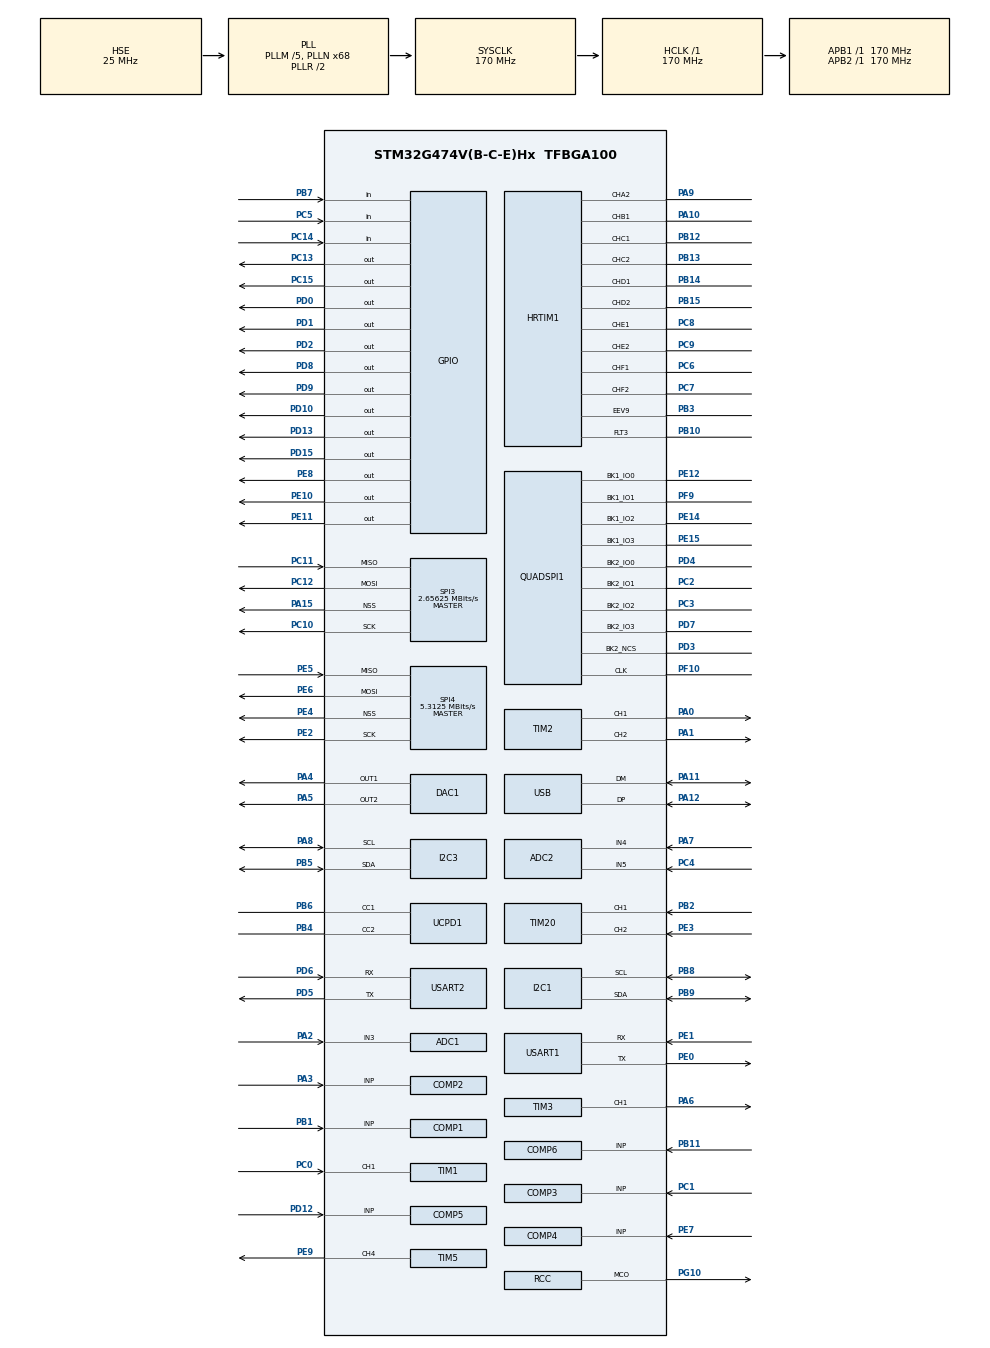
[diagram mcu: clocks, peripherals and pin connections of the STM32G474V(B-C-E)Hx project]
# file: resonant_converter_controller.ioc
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ADC1.Channel-1\#ChannelRegularConversion=ADC_CHANNEL_3
ADC1.EnableInjectedConversion=ENABLE
ADC1.ExternalTrigInjecConv=ADC_EXTERNALTRIGINJEC_T8_TRGO
ADC1.InjNumberOfConversion=1
ADC1.InjectedChannel-2\#ChannelInjectedConversion=ADC_CHANNEL_3
ADC1.InjectedOffsetNumber-2\#ChannelInjectedConversion=ADC_OFFSET_NONE
ADC1.InjectedRank-2\#ChannelInjectedConversion=1
ADC1.InjectedSamplingTime-2\#ChannelInjectedConversion=ADC_SAMPLETIME_2CYCLES_5
ADC1.NbrOfConversion=1
ADC1.NbrOfConversionFlag=1
ADC1.OffsetNumber-1\#ChannelRegularConversion=ADC_OFFSET_NONE
ADC1.Rank-1\#ChannelRegularConversion=1
ADC1.Rank1_Channel=ADC_CHANNEL_3
ADC1.Rank2_Channel=ADC_CHANNEL_3
ADC1.Rank3_Channel=ADC_CHANNEL_3
ADC1.SamplingTime-1\#ChannelRegularConversion=ADC_SAMPLETIME_2CYCLES_5
ADC1.master=1
ADC2.Channel-0\#ChannelRegularConversion=ADC_CHANNEL_4
ADC2.EnableInjectedConversion=ENABLE
ADC2.ExternalTrigInjecConv=ADC_EXTERNALTRIGINJEC_T8_TRGO
ADC2.InjNumberOfConversion=1
ADC2.InjectedChannel-1\#ChannelInjectedConversion=ADC_CHANNEL_4
ADC2.InjectedOffsetNumber-1\#ChannelInjectedConversion=ADC_OFFSET_NONE
ADC2.InjectedRank-1\#ChannelInjectedConversion=1
ADC2.InjectedSamplingTime-1\#ChannelInjectedConversion=ADC_SAMPLETIME_2CYCLES_5
ADC2.NbrOfConversion=1
ADC2.NbrOfConversionFlag=1
ADC2.OffsetNumber-0\#ChannelRegularConversion=ADC_OFFSET_NONE
ADC2.Rank-0\#ChannelRegularConversion=1
ADC2.Rank1_Channel=ADC_CHANNEL_4
ADC2.SamplingTime-0\#ChannelRegularConversion=ADC_SAMPLETIME_2CYCLES_5
ADC3.Channel-0\#ChannelRegularConversion=ADC_CHANNEL_9
ADC3.EnableInjectedConversion=ENABLE
ADC3.ExternalTrigInjecConv=ADC_EXTERNALTRIGINJEC_T8_TRGO
ADC3.InjNumberOfConversion=1
ADC3.InjectedChannel-1\#ChannelInjectedConversion=ADC_CHANNEL_9
ADC3.InjectedOffsetNumber-1\#ChannelInjectedConversion=ADC_OFFSET_NONE
ADC3.InjectedRank-1\#ChannelInjectedConversion=1
ADC3.InjectedSamplingTime-1\#ChannelInjectedConversion=ADC_SAMPLETIME_2CYCLES_5
ADC3.NbrOfConversionFlag=1
ADC3.OffsetNumber-0\#ChannelRegularConversion=ADC_OFFSET_NONE
ADC3.Rank-0\#ChannelRegularConversion=1
ADC3.Rank1_Channel=ADC_CHANNEL_9
ADC3.SamplingTime-0\#ChannelRegularConversion=ADC_SAMPLETIME_2CYCLES_5
ADC3.master=1
DAC1.DAC_Channel-DAC_OUT2=DAC_CHANNEL_2
DAC3.DAC_Channel-DAC_OUT2_Int=DAC_CHANNEL_2
DAC4.DAC_Channel-DAC_OUT2_Int=DAC_CHANNEL_2
Dma.ADC1.6.Direction=DMA_PERIPH_TO_MEMORY
Dma.ADC1.6.EventEnable=DISABLE
Dma.ADC1.6.Instance=DMA1_Channel7
Dma.ADC1.6.MemDataAlignment=DMA_MDATAALIGN_HALFWORD
Dma.ADC1.6.MemInc=DMA_MINC_ENABLE
Dma.ADC1.6.Mode=DMA_NORMAL
Dma.ADC1.6.PeriphDataAlignment=DMA_PDATAALIGN_HALFWORD
Dma.ADC1.6.PeriphInc=DMA_PINC_DISABLE
Dma.ADC1.6.Polarity=HAL_DMAMUX_REQ_GEN_RISING
Dma.ADC1.6.Priority=DMA_PRIORITY_HIGH
Dma.ADC1.6.RequestNumber=1
Dma.ADC1.6.SignalID=NONE
Dma.ADC1.6.SyncEnable=DISABLE
Dma.ADC1.6.SyncPolarity=HAL_DMAMUX_SYNC_NO_EVENT
Dma.ADC1.6.SyncRequestNumber=1
Dma.ADC1.6.SyncSignalID=NONE
Dma.ADC2.5.Direction=DMA_PERIPH_TO_MEMORY
Dma.ADC2.5.EventEnable=DISABLE
Dma.ADC2.5.Instance=DMA1_Channel6
Dma.ADC2.5.MemDataAlignment=DMA_MDATAALIGN_HALFWORD
Dma.ADC2.5.MemInc=DMA_MINC_ENABLE
Dma.ADC2.5.Mode=DMA_NORMAL
Dma.ADC2.5.PeriphDataAlignment=DMA_PDATAALIGN_HALFWORD
Dma.ADC2.5.PeriphInc=DMA_PINC_DISABLE
Dma.ADC2.5.Polarity=HAL_DMAMUX_REQ_GEN_RISING
Dma.ADC2.5.Priority=DMA_PRIORITY_HIGH
Dma.ADC2.5.RequestNumber=1
Dma.ADC2.5.SignalID=NONE
Dma.ADC2.5.SyncEnable=DISABLE
Dma.ADC2.5.SyncPolarity=HAL_DMAMUX_SYNC_NO_EVENT
Dma.ADC2.5.SyncRequestNumber=1
Dma.ADC2.5.SyncSignalID=NONE
Dma.ADC3.4.Direction=DMA_PERIPH_TO_MEMORY
Dma.ADC3.4.EventEnable=DISABLE
Dma.ADC3.4.Instance=DMA1_Channel5
Dma.ADC3.4.MemDataAlignment=DMA_MDATAALIGN_HALFWORD
Dma.ADC3.4.MemInc=DMA_MINC_ENABLE
Dma.ADC3.4.Mode=DMA_NORMAL
Dma.ADC3.4.PeriphDataAlignment=DMA_PDATAALIGN_HALFWORD
Dma.ADC3.4.PeriphInc=DMA_PINC_DISABLE
Dma.ADC3.4.Polarity=HAL_DMAMUX_REQ_GEN_RISING
Dma.ADC3.4.Priority=DMA_PRIORITY_HIGH
Dma.ADC3.4.RequestNumber=1
Dma.ADC3.4.SignalID=NONE
Dma.ADC3.4.SyncEnable=DISABLE
Dma.ADC3.4.SyncPolarity=HAL_DMAMUX_SYNC_NO_EVENT
Dma.ADC3.4.SyncRequestNumber=1
Dma.ADC3.4.SyncSignalID=NONE
Dma.DAC1_CH1.2.Direction=DMA_MEMORY_TO_PERIPH
Dma.DAC1_CH1.2.EventEnable=DISABLE
Dma.DAC1_CH1.2.Instance=DMA1_Channel3
Dma.DAC1_CH1.2.MemDataAlignment=DMA_MDATAALIGN_HALFWORD
Dma.DAC1_CH1.2.MemInc=DMA_MINC_ENABLE
Dma.DAC1_CH1.2.Mode=DMA_NORMAL
Dma.DAC1_CH1.2.PeriphDataAlignment=DMA_PDATAALIGN_WORD
Dma.DAC1_CH1.2.PeriphInc=DMA_PINC_DISABLE
Dma.DAC1_CH1.2.Polarity=HAL_DMAMUX_REQ_GEN_RISING
Dma.DAC1_CH1.2.Priority=DMA_PRIORITY_LOW
Dma.DAC1_CH1.2.RequestNumber=1
Dma.DAC1_CH1.2.SignalID=NONE
Dma.DAC1_CH1.2.SyncEnable=DISABLE
Dma.DAC1_CH1.2.SyncPolarity=HAL_DMAMUX_SYNC_NO_EVENT
Dma.DAC1_CH1.2.SyncRequestNumber=1
Dma.DAC1_CH1.2.SyncSignalID=NONE
Dma.DAC1_CH2.3.Direction=DMA_MEMORY_TO_PERIPH
Dma.DAC1_CH2.3.EventEnable=DISABLE
Dma.DAC1_CH2.3.Instance=DMA1_Channel4
Dma.DAC1_CH2.3.MemDataAlignment=DMA_MDATAALIGN_HALFWORD
Dma.DAC1_CH2.3.MemInc=DMA_MINC_ENABLE
Dma.DAC1_CH2.3.Mode=DMA_NORMAL
Dma.DAC1_CH2.3.PeriphDataAlignment=DMA_PDATAALIGN_WORD
Dma.DAC1_CH2.3.PeriphInc=DMA_PINC_DISABLE
Dma.DAC1_CH2.3.Polarity=HAL_DMAMUX_REQ_GEN_RISING
Dma.DAC1_CH2.3.Priority=DMA_PRIORITY_LOW
Dma.DAC1_CH2.3.RequestNumber=1
Dma.DAC1_CH2.3.SignalID=NONE
Dma.DAC1_CH2.3.SyncEnable=DISABLE
Dma.DAC1_CH2.3.SyncPolarity=HAL_DMAMUX_SYNC_NO_EVENT
Dma.DAC1_CH2.3.SyncRequestNumber=1
Dma.DAC1_CH2.3.SyncSignalID=NONE
Dma.QUADSPI.7.Direction=DMA_MEMORY_TO_PERIPH
Dma.QUADSPI.7.EventEnable=DISABLE
Dma.QUADSPI.7.Instance=DMA1_Channel8
Dma.QUADSPI.7.MemDataAlignment=DMA_MDATAALIGN_BYTE
Dma.QUADSPI.7.MemInc=DMA_MINC_ENABLE
Dma.QUADSPI.7.Mode=DMA_NORMAL
Dma.QUADSPI.7.PeriphDataAlignment=DMA_PDATAALIGN_HALFWORD
Dma.QUADSPI.7.PeriphInc=DMA_PINC_DISABLE
Dma.QUADSPI.7.Polarity=HAL_DMAMUX_REQ_GEN_RISING
Dma.QUADSPI.7.Priority=DMA_PRIORITY_VERY_HIGH
Dma.QUADSPI.7.RequestNumber=1
Dma.QUADSPI.7.SignalID=NONE
Dma.QUADSPI.7.SyncEnable=DISABLE
Dma.QUADSPI.7.SyncPolarity=HAL_DMAMUX_SYNC_NO_EVENT
Dma.QUADSPI.7.SyncRequestNumber=1
Dma.QUADSPI.7.SyncSignalID=NONE
Dma.Request0=UCPD1_RX
Dma.Request1=UCPD1_TX
Dma.Request2=DAC1_CH1
Dma.Request3=DAC1_CH2
Dma.Request4=ADC3
Dma.Request5=ADC2
Dma.Request6=ADC1
Dma.Request7=QUADSPI
Dma.UCPD1_RX.0.Direction=DMA_PERIPH_TO_MEMORY
Dma.UCPD1_RX.0.EventEnable=DISABLE
Dma.UCPD1_RX.0.Instance=DMA1_Channel1
Dma.UCPD1_RX.0.MemDataAlignment=DMA_MDATAALIGN_BYTE
Dma.UCPD1_RX.0.MemInc=DMA_MINC_ENABLE
Dma.UCPD1_RX.0.Mode=DMA_NORMAL
Dma.UCPD1_RX.0.PeriphDataAlignment=DMA_PDATAALIGN_BYTE
Dma.UCPD1_RX.0.PeriphInc=DMA_PINC_DISABLE
Dma.UCPD1_RX.0.Polarity=HAL_DMAMUX_REQ_GEN_RISING
Dma.UCPD1_RX.0.Priority=DMA_PRIORITY_LOW
Dma.UCPD1_RX.0.RequestNumber=1
Dma.UCPD1_RX.0.SignalID=NONE
Dma.UCPD1_RX.0.SyncEnable=DISABLE
Dma.UCPD1_RX.0.SyncPolarity=HAL_DMAMUX_SYNC_NO_EVENT
Dma.UCPD1_RX.0.SyncRequestNumber=1
Dma.UCPD1_RX.0.SyncSignalID=NONE
Dma.UCPD1_TX.1.Direction=DMA_MEMORY_TO_PERIPH
Dma.UCPD1_TX.1.EventEnable=DISABLE
Dma.UCPD1_TX.1.Instance=DMA1_Channel2
Dma.UCPD1_TX.1.MemDataAlignment=DMA_MDATAALIGN_BYTE
Dma.UCPD1_TX.1.MemInc=DMA_MINC_ENABLE
Dma.UCPD1_TX.1.Mode=DMA_NORMAL
Dma.UCPD1_TX.1.PeriphDataAlignment=DMA_PDATAALIGN_BYTE
Dma.UCPD1_TX.1.PeriphInc=DMA_PINC_DISABLE
Dma.UCPD1_TX.1.Polarity=HAL_DMAMUX_REQ_GEN_RISING
Dma.UCPD1_TX.1.Priority=DMA_PRIORITY_LOW
Dma.UCPD1_TX.1.RequestNumber=1
Dma.UCPD1_TX.1.SignalID=NONE
Dma.UCPD1_TX.1.SyncEnable=DISABLE
Dma.UCPD1_TX.1.SyncPolarity=HAL_DMAMUX_SYNC_NO_EVENT
Dma.UCPD1_TX.1.SyncRequestNumber=1
Dma.UCPD1_TX.1.SyncSignalID=NONE
FREERTOS.Tasks01=defaultTask,24,128,StartDefaultTask,Default,NULL,Dynamic,NULL,NULL
HRTIM1.Event_EEV1=HRTIM_EVENT_1
HRTIM1.Event_EEV2=HRTIM_EVENT_2
HRTIM1.Event_EEV3=__NULL
HRTIM1.Event_EEV4=HRTIM_EVENT_4
HRTIM1.Event_EEV5=HRTIM_EVENT_5
HRTIM1.Event_EEV8=HRTIM_EVENT_8
I2C1.Timing=0x40B285C2
I2C3.Timing=0x40B285C2
Mcu.Family=STM32G4
Mcu.Name=STM32G474V(B-C-E)Hx
Mcu.Package=TFBGA100
NVIC.DMA1_Channel1_IRQn=true\:5\:0\:false\:false\:true\:true\:false\:true\:true
NVIC.DMA1_Channel2_IRQn=true\:5\:0\:false\:false\:true\:true\:false\:true\:true
NVIC.DMA1_Channel3_IRQn=true\:5\:0\:false\:false\:true\:true\:false\:true\:true
NVIC.DMA1_Channel4_IRQn=true\:5\:0\:false\:false\:true\:true\:false\:true\:true
NVIC.DMA1_Channel5_IRQn=true\:5\:0\:false\:false\:true\:true\:false\:true\:true
NVIC.DMA1_Channel6_IRQn=true\:5\:0\:false\:false\:true\:true\:false\:true\:true
NVIC.DMA1_Channel7_IRQn=true\:5\:0\:false\:false\:true\:true\:false\:true\:true
NVIC.DMA1_Channel8_IRQn=true\:5\:0\:false\:false\:true\:true\:false\:true\:true
NVIC.PriorityGroup=NVIC_PRIORITYGROUP_4
NVIC.TIM7_DAC_IRQn=true\:15\:0\:false\:false\:true\:false\:false\:true\:true
NVIC.TimeBase=TIM7_DAC_IRQn
NVIC.TimeBaseIP=TIM7
NVIC.UCPD1_IRQn=true\:5\:0\:false\:false\:true\:true\:true\:false\:true
NVIC.USB_LP_IRQn=true\:5\:0\:false\:false\:true\:true\:false\:true\:true
PA0.Signal=S_TIM2_CH1
PA1.Signal=S_TIM2_CH2
PA10.Mode=Output_TB1
PA10.Signal=HRTIM1_CHB1
PA11.Mode=Device
PA11.Signal=USB_DM
PA12.Mode=Device
PA12.Signal=USB_DP
PA13.Mode=Serial_Wire
PA13.Signal=SYS_JTMS-SWDIO
PA14.Mode=Serial_Wire
PA14.Signal=SYS_JTCK-SWCLK
PA15.Mode=NSS_Signal_Hard_Output
PA15.Signal=SPI3_NSS
PA2.Mode=IN3-Single-Ended
PA2.Signal=ADC1_IN3
PA3.Signal=SharedAnalog_PA3
PA4.Signal=COMP_DAC11_group
PA5.Signal=COMP_DAC12_group
PA6.Signal=S_TIM3_CH1
PA7.Mode=IN4-Single-Ended
PA7.Signal=ADC2_IN4
PA8.Mode=I2C
PA8.Signal=I2C3_SCL
PA9.Mode=Output_TA2
PA9.Signal=HRTIM1_CHA2
PB1.Signal=SharedAnalog_PB1
PB10.Mode=Fault_Enable3
PB10.Signal=HRTIM1_FLT3
PB11.Signal=SharedAnalog_PB11
PB12.Mode=Output_TC1TC2
PB12.Signal=HRTIM1_CHC1
PB13.Mode=Output_TC1TC2
PB13.Signal=HRTIM1_CHC2
PB14.Mode=Output_TD1TD2
PB14.Signal=HRTIM1_CHD1
PB15.Mode=Output_TD1TD2
PB15.Signal=HRTIM1_CHD2
PB2.Signal=S_TIM20_CH1
PB3.Mode=External_Evt_enable9
PB3.Signal=HRTIM1_EEV9
PB4.Mode=Dual_Role_AllSignals
PB4.Signal=UCPD1_CC2
PB5.Mode=I2C
PB5.Signal=I2C3_SDA
PB6.Mode=Dual_Role_AllSignals
PB6.Signal=UCPD1_CC1
PB7.Signal=GPIO_Input
PB8-BOOT0.Mode=I2C
PB8-BOOT0.Signal=I2C1_SCL
PB9.Mode=I2C
PB9.Signal=I2C1_SDA
PC0.Signal=S_TIM1_CH1
PC1.Signal=SharedAnalog_PC1
PC10.Mode=Full_Duplex_Master
PC10.Signal=SPI3_SCK
PC11.Mode=Full_Duplex_Master
PC11.Signal=SPI3_MISO
PC12.Mode=Full_Duplex_Master
PC12.Signal=SPI3_MOSI
PC13.Signal=GPIO_Output
PC14-OSC32_IN.Signal=GPIO_Input
PC15-OSC32_OUT.Signal=GPIO_Output
PC2.Mode=Dual Bank
PC2.Signal=QUADSPI1_BK2_IO1
PC3.Mode=Dual Bank
PC3.Signal=QUADSPI1_BK2_IO2
PC4.Mode=IN5-Single-Ended
PC4.Signal=ADC2_IN5
PC5.Signal=GPIO_Input
PC6.Mode=Output_TF1TF2
PC6.Signal=HRTIM1_CHF1
PC7.Mode=Output_TF1TF2
PC7.Signal=HRTIM1_CHF2
PC8.Mode=Output_TE1TE2
PC8.Signal=HRTIM1_CHE1
PC9.Mode=Output_TE1TE2
PC9.Signal=HRTIM1_CHE2
PD0.Signal=GPIO_Output
PD1.Signal=GPIO_Output
PD10.Signal=GPIO_Output
PD12.Signal=SharedAnalog_PD12
PD13.Signal=GPIO_Output
PD15.Signal=GPIO_Output
PD2.Signal=GPIO_Output
PD3.Mode=Enable Chip Select 2 for both banks
PD3.Signal=QUADSPI1_BK2_NCS
PD4.Mode=Dual Bank
PD4.Signal=QUADSPI1_BK2_IO0
PD5.Mode=Asynchronous
PD5.Signal=USART2_TX
PD6.Mode=Asynchronous
PD6.Signal=USART2_RX
PD7.Mode=Dual Bank
PD7.Signal=QUADSPI1_BK2_IO3
PD8.Signal=GPIO_Output
PD9.Signal=GPIO_Output
PE0.Mode=Asynchronous
PE0.Signal=USART1_TX
PE1.Mode=Asynchronous
PE1.Signal=USART1_RX
PE10.Signal=GPIO_Output
PE11.Signal=GPIO_Output
PE12.Mode=Dual Bank
PE12.Signal=QUADSPI1_BK1_IO0
PE14.Mode=Dual Bank
PE14.Signal=QUADSPI1_BK1_IO2
PE15.Mode=Dual Bank
PE15.Signal=QUADSPI1_BK1_IO3
PE2.Mode=Full_Duplex_Master
PE2.Signal=SPI4_SCK
PE3.Signal=S_TIM20_CH2
PE4.Mode=NSS_Signal_Hard_Output
PE4.Signal=SPI4_NSS
PE5.Mode=Full_Duplex_Master
PE5.Signal=SPI4_MISO
PE6.Mode=Full_Duplex_Master
PE6.Signal=SPI4_MOSI
PE7.Signal=SharedAnalog_PE7
PE8.Signal=GPIO_Output
PE9.Signal=S_TIM5_CH4
PF0-OSC_IN.Mode=HSE-External-Oscillator
PF0-OSC_IN.Signal=RCC_OSC_IN
PF1-OSC_OUT.Mode=HSE-External-Oscillator
PF1-OSC_OUT.Signal=RCC_OSC_OUT
PF10.Mode=Dual Bank
PF10.Signal=QUADSPI1_CLK
PF9.Mode=Dual Bank
PF9.Signal=QUADSPI1_BK1_IO1
PG10-NRST.Mode=Clock-out
PG10-NRST.Signal=RCC_MCO
ProjectManager.HeapSize=0x200
ProjectManager.StackSize=0x400
ProjectManager.TargetToolchain=CMake
RCC.ADC12Freq_Value=170000000
RCC.ADC345Freq_Value=170000000
RCC.AHBFreq_Value=170000000
RCC.APB1Freq_Value=170000000
RCC.APB1TimFreq_Value=170000000
RCC.APB2Freq_Value=170000000
RCC.APB2TimFreq_Value=170000000
RCC.CK48CLockSelection=RCC_USBCLKSOURCE_HSI48
RCC.CortexFreq_Value=170000000
RCC.EXTERNAL_CLOCK_VALUE=12288000
RCC.HCLKFreq_Value=170000000
RCC.HSE_VALUE=25000000
RCC.HSI48_VALUE=48000000
RCC.HSI_VALUE=16000000
RCC.LSE_VALUE=32768
RCC.PLLM=RCC_PLLM_DIV5
RCC.PLLN=68
RCC.PLLQ=RCC_PLLQ_DIV8
RCC.PLLSourceVirtual=RCC_PLLSOURCE_HSE
RCC.PREFETCH_ENABLE=1
RCC.RCC_MCO1Source=RCC_MCO1SOURCE_HSE
RCC.SYSCLKFreq_VALUE=170000000
RCC.SYSCLKSource=RCC_SYSCLKSOURCE_PLLCLK
RCC.USBFreq_Value=48000000
RCC.VCOOutputFreq_Value=340000000
SH.COMP_DAC11_group.0=DAC1_OUT1,DAC_OUT1
SH.COMP_DAC12_group.0=DAC1_OUT2,DAC_OUT2
SH.S_TIM1_CH1.0=TIM1_CH1,TriggerSource_TI1ED
SH.S_TIM20_CH1.0=TIM20_CH1,Encoder_Interface
SH.S_TIM20_CH2.0=TIM20_CH2,Encoder_Interface
SH.S_TIM2_CH1.0=TIM2_CH1,PWM Generation1 CH1
SH.S_TIM2_CH2.0=TIM2_CH2,PWM Generation2 CH2
SH.S_TIM3_CH1.0=TIM3_CH1,PWM Generation1 CH1
SH.S_TIM5_CH4.0=TIM5_CH4,PWM Generation4 CH4
SH.SharedAnalog_PA3.0=ADC1_IN4
SH.SharedAnalog_PA3.1=COMP2_INP,INP
SH.SharedAnalog_PB1.0=ADC3_IN1
SH.SharedAnalog_PB1.1=COMP1_INP,INP
SH.SharedAnalog_PB11.0=COMP6_INP,INP
SH.SharedAnalog_PB11.1=ADC1_IN14,IN14-Single-Ended
SH.SharedAnalog_PC1.0=ADC1_IN7
SH.SharedAnalog_PC1.1=COMP3_INP,INP
SH.SharedAnalog_PD12.0=COMP5_INP,INP
SH.SharedAnalog_PD12.1=ADC3_IN9,IN9-Single-Ended
SH.SharedAnalog_PE7.0=ADC3_IN4
SH.SharedAnalog_PE7.1=COMP4_INP,INP
SPI3.BaudRatePrescaler=SPI_BAUDRATEPRESCALER_64
SPI3.CalculateBaudRate=2.65625 MBits/s
SPI3.Direction=SPI_DIRECTION_2LINES
SPI3.Mode=SPI_MODE_MASTER
SPI3.VirtualNSS=VM_NSSHARD
SPI3.VirtualType=VM_MASTER
SPI4.BaudRatePrescaler=SPI_BAUDRATEPRESCALER_32
SPI4.CalculateBaudRate=5.3125 MBits/s
SPI4.Direction=SPI_DIRECTION_2LINES
SPI4.Mode=SPI_MODE_MASTER
SPI4.VirtualNSS=VM_NSSHARD
SPI4.VirtualType=VM_MASTER
SYS.TrimmingMode=__NULL
SYS.VoltageScaling=SYSCFG_VREFBUF_VOLTAGE_SCALE2
TIM1.Channel-Input_Capture1_from_TRC=TIM_CHANNEL_1
TIM2.Channel-PWM\ Generation1\ CH1=TIM_CHANNEL_1
TIM2.Channel-PWM\ Generation2\ CH2=TIM_CHANNEL_2
TIM3.Channel-PWM\ Generation1\ CH1=TIM_CHANNEL_1
TIM5.Channel-PWM\ Generation4\ CH4=TIM_CHANNEL_4
TIM8.TIM_MasterOutputTrigger=TIM_TRGO_UPDATE
USART1.VirtualMode-Asynchronous=VM_ASYNC
USART2.VirtualMode-Asynchronous=VM_ASYNC
USBPD.USBPD_PORT0_PDO_SNK_FIXED_SET_OP_CURRENT_0=2000
USB_DEVICE.CLASS_NAME_FS=CDC
USB_DEVICE.VirtualMode=Cdc
USB_DEVICE.VirtualModeFS=Cdc_FS
VP_COMP1_VS_DAC3OUT1.Mode=INM_DAC3OUT1
VP_COMP2_VS_DAC3OUT2.Mode=INM_DAC3OUT2
VP_COMP3_VS_DAC3OUT1.Mode=INM_DAC3OUT1
VP_COMP4_VS_DAC3OUT2.Mode=INM_DAC3OUT2
VP_COMP5_VS_DAC4OUT1.Mode=INM_DAC4OUT1
VP_COMP6_VS_DAC4OUT2.Mode=INM_DAC4OUT2
VP_CRC_VS_CRC.Mode=CRC_Activate
VP_DAC2_VS_DACI1.Mode=DAC_OUT1_Int
VP_DAC3_VS_DACI1.Mode=DAC_OUT1_Int
VP_DAC3_VS_DACI2.Mode=DAC_OUT2_Int
VP_DAC4_VS_DACI1.Mode=DAC_OUT1_Int
VP_DAC4_VS_DACI2.Mode=DAC_OUT2_Int
VP_FATFS_VS_Generic.Mode=User_defined
VP_FREERTOS_VS_CMSIS_V2.Mode=CMSIS_V2
VP_HRTIM1_VS_hrtimMasterTimerNoOutput.Mode=MasterTimer
VP_HRTIM1_VirtualSync.Mode=SCOUT_SCINmodeVirtual
VP_SYS_VS_DBSignals.Mode=DisableDeadBatterySignals
VP_SYS_VS_tim7.Mode=TIM7
VP_TIM1_VS_CH1.Mode=Input_Capture1_from_TRC
VP_TIM1_VS_ClockSourceINT.Mode=Internal
VP_TIM1_VS_ControllerModeTrigger.Mode=Trigger Mode
VP_TIM2_VS_ClockSourceINT.Mode=Internal
VP_TIM3_VS_ClockSourceINT.Mode=Internal
VP_TIM5_VS_ClockSourceINT.Mode=Internal
VP_TIM8_VS_ClockSourceINT.Mode=Internal
VP_USBPD_VS_PD3FULL.Mode=PD3_Full_Stack
VP_USBPD_VS_USBPD1.Mode=USBPD_P0
VP_USBPD_VS_usbpd_tim4.Mode=TIM4
VP_USB_DEVICE_VS_USB_DEVICE_CDC_FS.Mode=CDC_FS
VREF+.Mode=InternalMode
VREF+.Signal=VREFBUF_OUT
board=custom

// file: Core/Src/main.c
/* USER CODE BEGIN Header */
/**
  ******************************************************************************
  * @file           : main.c
  * @brief          : Main program body
  ******************************************************************************
  * @attention
  *
  * Copyright (c) 2025 STMicroelectronics.
  * All rights reserved.
  *
  * This software is licensed under terms that can be found in the LICENSE file
  * in the root directory of this software component.
  * If no LICENSE file comes with this software, it is provided AS-IS.
  *
  ******************************************************************************
  */
/* USER CODE END Header */
#include "main.h"
#include "cmsis_os.h"
#include "app_fatfs.h"
#include "usbpd.h"
#include "usb_device.h"

/* USER CODE BEGIN Includes */

#include "board.h"
#include "usbpd_app.h"
#include "usbpd_dpm_core.h"

/* USER CODE END Includes */

ADC_HandleTypeDef hadc1;
ADC_HandleTypeDef hadc2;
ADC_HandleTypeDef hadc3;
DMA_HandleTypeDef hdma_adc1;
DMA_HandleTypeDef hdma_adc2;
DMA_HandleTypeDef hdma_adc3;

COMP_HandleTypeDef hcomp1;
COMP_HandleTypeDef hcomp2;
COMP_HandleTypeDef hcomp3;
COMP_HandleTypeDef hcomp4;
COMP_HandleTypeDef hcomp5;
COMP_HandleTypeDef hcomp6;

CRC_HandleTypeDef hcrc;

DAC_HandleTypeDef hdac1;
DAC_HandleTypeDef hdac2;
DAC_HandleTypeDef hdac3;
DAC_HandleTypeDef hdac4;
DMA_HandleTypeDef hdma_dac1_ch1;
DMA_HandleTypeDef hdma_dac1_ch2;

HRTIM_HandleTypeDef hhrtim1;

I2C_HandleTypeDef hi2c1;
I2C_HandleTypeDef hi2c3;

QSPI_HandleTypeDef hqspi1;
DMA_HandleTypeDef hdma_quadspi;

SPI_HandleTypeDef hspi3;
SPI_HandleTypeDef hspi4;

TIM_HandleTypeDef htim1;
TIM_HandleTypeDef htim2;
TIM_HandleTypeDef htim3;
TIM_HandleTypeDef htim5;
TIM_HandleTypeDef htim8;
TIM_HandleTypeDef htim20;

UART_HandleTypeDef huart1;
UART_HandleTypeDef huart2;

/* Definitions for defaultTask */
osThreadId_t defaultTaskHandle;
const osThreadAttr_t defaultTask_attributes = {
  .name = "defaultTask",
  .priority = (osPriority_t) osPriorityNormal,
  .stack_size = 128 * 4
};
/* USER CODE BEGIN PV */
// Board definition macro (selected by CMake -DBOARD=...)
#define resonance_converter_controller

/* Board config - pointers for board.h extern declarations */
HRTIM_HandleTypeDef *g_board_hrtim = &hhrtim1;
const uint32_t g_board_hrtim_out1 = HRTIM_OUTPUT_TA2;
const uint32_t g_board_hrtim_out2 = HRTIM_OUTPUT_TB1;
const uint32_t g_board_hrtim_out3 = HRTIM_OUTPUT_TC1;
const uint32_t g_board_hrtim_out4 = HRTIM_OUTPUT_TC2;
const uint32_t g_board_hrtim_sync_out1_p = HRTIM_OUTPUT_TD1;
const uint32_t g_board_hrtim_sync_out1_n = HRTIM_OUTPUT_TD2;
const uint32_t g_board_hrtim_sync_out2_p = HRTIM_OUTPUT_TE1;
const uint32_t g_board_hrtim_sync_out2_n = HRTIM_OUTPUT_TE2;
const uint32_t g_board_hrtim_sync_out3_p = HRTIM_OUTPUT_TF1;
const uint32_t g_board_hrtim_sync_out3_n = HRTIM_OUTPUT_TF2;
const uint32_t g_board_hrtim_delayd_eev1 = HRTIM_EVENT_9;
const uint32_t g_board_hrtim_flt = HRTIM_FAULT_3;

TIM_HandleTypeDef *g_board_tim_feedback = &htim1;
const uint32_t g_board_tim_feedback_channel = TIM_CHANNEL_1;

TIM_HandleTypeDef *g_board_aux_pwm = &htim2;
const uint32_t g_board_aux_pwm_cha = TIM_CHANNEL_1;
const uint32_t g_board_aux_pwm_chb = TIM_CHANNEL_2;

TIM_HandleTypeDef *g_board_tim_fan_pwm = &htim3;
const uint32_t g_board_tim_fan_pwm_channel = TIM_CHANNEL_1;

TIM_HandleTypeDef *g_board_tim_ws2812b = &htim5;
const uint32_t g_board_tim_ws2812b_channel = TIM_CHANNEL_4;

TIM_HandleTypeDef *g_board_tim_encoder = &htim20;

TIM_HandleTypeDef *g_board_tim_adc_trgo = &htim8;

I2C_HandleTypeDef *g_board_i2c_internal = &hi2c1;
I2C_HandleTypeDef *g_board_i2c_external = &hi2c3;
SPI_HandleTypeDef *g_board_lcd_spi = &hspi3;
SPI_HandleTypeDef *g_board_sdcard_spi = &hspi4;
QSPI_HandleTypeDef *g_board_psram_qspi = &hqspi1;
UART_HandleTypeDef *g_board_ctl_uart = &huart1;
UART_HandleTypeDef *g_board_aux_uart = &huart2;

CRC_HandleTypeDef *g_board_crc32 = &hcrc;

DAC_HandleTypeDef *g_board_dac_ch1 = &hdac1;
DAC_HandleTypeDef *g_board_dac_ch2 = &hdac2;
DAC_HandleTypeDef *g_board_dac_ch3 = &hdac3;
DAC_HandleTypeDef *g_board_dac_ch4 = &hdac4;
DAC_HandleTypeDef *g_board_dac_channels[4] = { &hdac1, &hdac2, &hdac3, &hdac4 };

// BOARD_CONFIG instance - references to board peripherals
struct BoardConfig g_board_config = {
    .message_bus = &huart1,
    .crc32 = &hcrc
};

DAC_channel_t g_board_fb_sync_v = {
    .DACx = &hdac1, .channel = DAC_CHANNEL_2
};
DAC_channel_t g_board_dac_aux_v = {
    .DACx = &hdac1, .channel = DAC_CHANNEL_1
};
DAC_channel_t g_board_fb_ocd_comp_v = {
    .DACx = &hdac4, .channel = DAC_CHANNEL_2
};
DAC_channel_t g_board_fb_ocd2_comp_v = {
    .DACx = &hdac4, .channel = DAC_CHANNEL_1
};

ADC_channel_t g_board_aux_adc_read_v = {
    .ADCx = &hadc2, .channel = ADC_CHANNEL_4
};
ADC_channel_t g_board_dac_aux_read_back_v = {
    .ADCx = &hadc2, .channel = ADC_CHANNEL_5
};

ADC_channel_t g_board_fb_ocd_read_v = {
    .ADCx = &hadc1, .channel = ADC_CHANNEL_14
};
ADC_channel_t g_board_fb_ocd2_read_v = {
    .ADCx = &hadc3, .channel = ADC_CHANNEL_9
};

ADC_channel_t g_board_vsense_read_v = {
    .ADCx = &hadc3, .channel = ADC_CHANNEL_3
};

DAC_channel_t g_board_isense_comp_v[4] = {
    { .DACx = &hdac3, .channel = DAC_CHANNEL_2 },
    { .DACx = &hdac3, .channel = DAC_CHANNEL_2 },
    { .DACx = &hdac3, .channel = DAC_CHANNEL_1 },
    { .DACx = &hdac3, .channel = DAC_CHANNEL_1 },
};

COMP_HandleTypeDef *g_board_isense[4] = {
    &hcomp2,
    &hcomp4,
    &hcomp1,
    &hcomp3,
};
COMP_HandleTypeDef *g_board_fb_ocd2 = &hcomp5;
COMP_HandleTypeDef *g_board_fb_ocd = &hcomp6;

GPIO_pin_t g_board_gpios[8] = {
    { .GPIOx = GPIOD, .pin = GPIO_PIN_10 },
    { .GPIOx = GPIOD, .pin = GPIO_PIN_9 },
    { .GPIOx = GPIOD, .pin = GPIO_PIN_13 },
    { .GPIOx = GPIOD, .pin = GPIO_PIN_15 },
    { .GPIOx = GPIOE, .pin = GPIO_PIN_8 },
    { .GPIOx = GPIOD, .pin = GPIO_PIN_8 },
    { .GPIOx = GPIOE, .pin = GPIO_PIN_11 },
    { .GPIOx = GPIOE, .pin = GPIO_PIN_10 },
};
GPIO_pin_t g_board_power_int = {
    .GPIOx = GPIOC, .pin = GPIO_PIN_14
};
GPIO_pin_t g_board_vout_enable = {
    .GPIOx = GPIOC, .pin = GPIO_PIN_15
};
/* PC13 = BRIDGE_VOUT_VBUS_USB: high enables U26 (TPS259474A eFuse, VOUT -> VBUS_USBC,
   3 A limit, reverse blocking). 10 k pull-down: off at reset. Driven by PowerPath. */
GPIO_pin_t g_board_usb_vout_bridge = {
    .GPIOx = GPIOC, .pin = GPIO_PIN_13
};
GPIO_pin_t g_board_sdcard_detect = {
    .GPIOx = GPIOB, .pin = GPIO_PIN_7
};
GPIO_pin_t g_board_mco_nrst_sel = {
    .GPIOx = GPIOB, .pin = GPIO_PIN_2
};
GPIO_pin_t g_board_usb_dap_en = {
    .GPIOx = GPIOD, .pin = GPIO_PIN_11
};
GPIO_pin_t g_board_usb_dap_dir = {
    .GPIOx = GPIOD, .pin = GPIO_PIN_14
};
GPIO_pin_t g_board_lcd_bl = {
    .GPIOx = GPIOD, .pin = GPIO_PIN_0
};
/* PD0 is the USB_DEAD_BATT_DISABLE net (there is no LCD backlight net; the CubeMX label is
   stale): low keeps the external dead-battery Rd on CC1/CC2. Driven by USBPD_DPM_UserInit. */
GPIO_pin_t g_board_usb_dead_batt_disable = {
    .GPIOx = GPIOD, .pin = GPIO_PIN_0
};
GPIO_pin_t g_board_lcd_dc = {
    .GPIOx = GPIOD, .pin = GPIO_PIN_1
};
GPIO_pin_t g_board_lcd_rst = {
    .GPIOx = GPIOD, .pin = GPIO_PIN_2
};
/* PA15 = LCD_SS (SSD1327 CS#), driven as a GPIO once CubeMX sets it to GPIO_Output
   (docs/lcd_ui.md); while it is still SPI3_NSS the hardware drives it. */
GPIO_pin_t g_board_lcd_cs = {
    .GPIOx = GPIOA, .pin = GPIO_PIN_15
};
GPIO_pin_t g_board_key_int = {
    .GPIOx = GPIOC, .pin = GPIO_PIN_5
};

/* USER CODE END PV */

void SystemClock_Config(void);
static void MX_GPIO_Init(void);
static void MX_DMA_Init(void);
static void MX_COMP4_Init(void);
static void MX_DAC1_Init(void);
static void MX_DAC3_Init(void);
static void MX_HRTIM1_Init(void);
static void MX_I2C1_Init(void);
static void MX_I2C3_Init(void);
static void MX_QUADSPI1_Init(void);
static void MX_SPI4_Init(void);
static void MX_TIM1_Init(void);
static void MX_TIM2_Init(void);
static void MX_UCPD1_Init(void);
static void MX_USART1_UART_Init(void);
static void MX_COMP1_Init(void);
static void MX_COMP2_Init(void);
static void MX_COMP3_Init(void);
static void MX_DAC4_Init(void);
static void MX_COMP6_Init(void);
static void MX_SPI3_Init(void);
static void MX_TIM20_Init(void);
static void MX_USART2_UART_Init(void);
static void MX_ADC1_Init(void);
static void MX_COMP5_Init(void);
static void MX_TIM3_Init(void);
static void MX_ADC2_Init(void);
static void MX_DAC2_Init(void);
static void MX_CRC_Init(void);
static void MX_TIM5_Init(void);
static void MX_ADC3_Init(void);
static void MX_TIM8_Init(void);
void StartDefaultTask(void *argument);

int main(void)
{

  /* MCU Configuration--------------------------------------------------------*/

  /* Reset of all peripherals, Initializes the Flash interface and the Systick. */
  HAL_Init();

  /* Configure the system clock */
  SystemClock_Config();

  /* Initialize all configured peripherals */
  MX_GPIO_Init();
  MX_DMA_Init();
  MX_COMP4_Init();
  MX_DAC1_Init();
  MX_DAC3_Init();
  MX_HRTIM1_Init();
  MX_I2C1_Init();
  MX_I2C3_Init();
  MX_QUADSPI1_Init();
  MX_SPI4_Init();
  MX_TIM1_Init();
  MX_TIM2_Init();
  MX_UCPD1_Init();
  MX_USART1_UART_Init();
  MX_COMP1_Init();
  MX_COMP2_Init();
  MX_COMP3_Init();
  MX_DAC4_Init();
  MX_COMP6_Init();
  MX_SPI3_Init();
  MX_TIM20_Init();
  MX_USART2_UART_Init();
  MX_ADC1_Init();
  MX_COMP5_Init();
  MX_TIM3_Init();
  MX_ADC2_Init();
  if (MX_FATFS_Init() != APP_OK) {
    Error_Handler();
  }
  MX_DAC2_Init();
  MX_CRC_Init();
  MX_TIM5_Init();
  MX_ADC3_Init();
  MX_TIM8_Init();
  /* USER CODE BEGIN 2 */
  /* USB-PD port settings (DRP toggling, Rp, swaps) overriding the generated DPM_Settings:
     CAD_Init inside MX_USBPD_Init reads them once */
  usbpd_port_early_init();
  /* USER CODE END 2 */

  /* Init scheduler */
  osKernelInitialize();
  /* USBPD initialisation ---------------------------------*/
  MX_USBPD_Init();

  /* Create the thread(s) */
  /* creation of defaultTask */
  defaultTaskHandle = osThreadNew(StartDefaultTask, NULL, &defaultTask_attributes);

  /* Start scheduler */
  osKernelStart();

  /* We should never get here as control is now taken by the scheduler */

  /* Infinite loop */
  while (1)
  {

  }
}

void SystemClock_Config(void)
{
  RCC_OscInitTypeDef RCC_OscInitStruct = {0};
  RCC_ClkInitTypeDef RCC_ClkInitStruct = {0};

  /** Configure the main internal regulator output voltage
  */
  HAL_PWREx_ControlVoltageScaling(PWR_REGULATOR_VOLTAGE_SCALE1_BOOST);

  /** Initializes the RCC Oscillators according to the specified parameters
  * in the RCC_OscInitTypeDef structure.
  */
  RCC_OscInitStruct.OscillatorType = RCC_OSCILLATORTYPE_HSI|RCC_OSCILLATORTYPE_HSI48
                              |RCC_OSCILLATORTYPE_HSE;
  RCC_OscInitStruct.HSEState = RCC_HSE_ON;
  RCC_OscInitStruct.HSIState = RCC_HSI_ON;
  RCC_OscInitStruct.HSICalibrationValue = RCC_HSICALIBRATION_DEFAULT;
  RCC_OscInitStruct.HSI48State = RCC_HSI48_ON;
  RCC_OscInitStruct.PLL.PLLState = RCC_PLL_ON;
  RCC_OscInitStruct.PLL.PLLSource = RCC_PLLSOURCE_HSE;
  RCC_OscInitStruct.PLL.PLLM = RCC_PLLM_DIV5;
  RCC_OscInitStruct.PLL.PLLN = 68;
  RCC_OscInitStruct.PLL.PLLP = RCC_PLLP_DIV2;
  RCC_OscInitStruct.PLL.PLLQ = RCC_PLLQ_DIV8;
  RCC_OscInitStruct.PLL.PLLR = RCC_PLLR_DIV2;
  if (HAL_RCC_OscConfig(&RCC_OscInitStruct) != HAL_OK)
  {
    Error_Handler();
  }

  /** Initializes the CPU, AHB and APB buses clocks
  */
  RCC_ClkInitStruct.ClockType = RCC_CLOCKTYPE_HCLK|RCC_CLOCKTYPE_SYSCLK
                              |RCC_CLOCKTYPE_PCLK1|RCC_CLOCKTYPE_PCLK2;
  RCC_ClkInitStruct.SYSCLKSource = RCC_SYSCLKSOURCE_PLLCLK;
  RCC_ClkInitStruct.AHBCLKDivider = RCC_SYSCLK_DIV1;
  RCC_ClkInitStruct.APB1CLKDivider = RCC_HCLK_DIV1;
  RCC_ClkInitStruct.APB2CLKDivider = RCC_HCLK_DIV1;

  if (HAL_RCC_ClockConfig(&RCC_ClkInitStruct, FLASH_LATENCY_4) != HAL_OK)
  {
    Error_Handler();
  }
  HAL_RCC_MCOConfig(RCC_MCO_PG10, RCC_MCO1SOURCE_HSE, RCC_MCODIV_1);
}

static void MX_ADC1_Init(void)
{

  ADC_MultiModeTypeDef multimode = {0};
  ADC_ChannelConfTypeDef sConfig = {0};
  ADC_InjectionConfTypeDef sConfigInjected = {0};

  /** Common config
  */
  hadc1.Instance = ADC1;
  hadc1.Init.ClockPrescaler = ADC_CLOCK_SYNC_PCLK_DIV4;
  hadc1.Init.Resolution = ADC_RESOLUTION_12B;
  hadc1.Init.DataAlign = ADC_DATAALIGN_RIGHT;
  hadc1.Init.GainCompensation = 0;
  hadc1.Init.ScanConvMode = ADC_SCAN_DISABLE;
  hadc1.Init.EOCSelection = ADC_EOC_SINGLE_CONV;
  hadc1.Init.LowPowerAutoWait = DISABLE;
  hadc1.Init.ContinuousConvMode = DISABLE;
  hadc1.Init.NbrOfConversion = 1;
  hadc1.Init.DiscontinuousConvMode = DISABLE;
  hadc1.Init.ExternalTrigConv = ADC_SOFTWARE_START;
  hadc1.Init.ExternalTrigConvEdge = ADC_EXTERNALTRIGCONVEDGE_NONE;
  hadc1.Init.DMAContinuousRequests = DISABLE;
  hadc1.Init.Overrun = ADC_OVR_DATA_PRESERVED;
  hadc1.Init.OversamplingMode = DISABLE;
  if (HAL_ADC_Init(&hadc1) != HAL_OK)
  {
    Error_Handler();
  }

  /** Configure the ADC multi-mode
  */
  multimode.Mode = ADC_MODE_INDEPENDENT;
  if (HAL_ADCEx_MultiModeConfigChannel(&hadc1, &multimode) != HAL_OK)
  {
    Error_Handler();
  }

  /** Configure Regular Channel
  */
  sConfig.Channel = ADC_CHANNEL_3;
  sConfig.Rank = ADC_REGULAR_RANK_1;
  sConfig.SamplingTime = ADC_SAMPLETIME_2CYCLES_5;
  sConfig.SingleDiff = ADC_SINGLE_ENDED;
  sConfig.OffsetNumber = ADC_OFFSET_NONE;
  sConfig.Offset = 0;
  if (HAL_ADC_ConfigChannel(&hadc1, &sConfig) != HAL_OK)
  {
    Error_Handler();
  }

  /** Configure Injected Channel
  */
  sConfigInjected.InjectedChannel = ADC_CHANNEL_3;
  sConfigInjected.InjectedRank = ADC_INJECTED_RANK_1;
  sConfigInjected.InjectedSamplingTime = ADC_SAMPLETIME_2CYCLES_5;
  sConfigInjected.InjectedSingleDiff = ADC_SINGLE_ENDED;
  sConfigInjected.InjectedOffsetNumber = ADC_OFFSET_NONE;
  sConfigInjected.InjectedOffset = 0;
  sConfigInjected.InjectedNbrOfConversion = 1;
  sConfigInjected.InjectedDiscontinuousConvMode = DISABLE;
  sConfigInjected.AutoInjectedConv = DISABLE;
  sConfigInjected.QueueInjectedContext = DISABLE;
  sConfigInjected.ExternalTrigInjecConv = ADC_EXTERNALTRIGINJEC_T8_TRGO;
  sConfigInjected.ExternalTrigInjecConvEdge = ADC_EXTERNALTRIGINJECCONV_EDGE_RISING;
  sConfigInjected.InjecOversamplingMode = DISABLE;
  if (HAL_ADCEx_InjectedConfigChannel(&hadc1, &sConfigInjected) != HAL_OK)
  {
    Error_Handler();
  }

}

static void MX_ADC2_Init(void)
{

  ADC_ChannelConfTypeDef sConfig = {0};
  ADC_InjectionConfTypeDef sConfigInjected = {0};

  /** Common config
  */
  hadc2.Instance = ADC2;
  hadc2.Init.ClockPrescaler = ADC_CLOCK_SYNC_PCLK_DIV4;
  hadc2.Init.Resolution = ADC_RESOLUTION_12B;
  hadc2.Init.DataAlign = ADC_DATAALIGN_RIGHT;
  hadc2.Init.GainCompensation = 0;
  hadc2.Init.ScanConvMode = ADC_SCAN_DISABLE;
  hadc2.Init.EOCSelection = ADC_EOC_SINGLE_CONV;
  hadc2.Init.LowPowerAutoWait = DISABLE;
  hadc2.Init.ContinuousConvMode = DISABLE;
  hadc2.Init.NbrOfConversion = 1;
  hadc2.Init.DiscontinuousConvMode = DISABLE;
  hadc2.Init.ExternalTrigConv = ADC_SOFTWARE_START;
  hadc2.Init.ExternalTrigConvEdge = ADC_EXTERNALTRIGCONVEDGE_NONE;
  hadc2.Init.DMAContinuousRequests = DISABLE;
  hadc2.Init.Overrun = ADC_OVR_DATA_PRESERVED;
  hadc2.Init.OversamplingMode = DISABLE;
  if (HAL_ADC_Init(&hadc2) != HAL_OK)
  {
    Error_Handler();
  }

  /** Configure Regular Channel
  */
  sConfig.Channel = ADC_CHANNEL_4;
  sConfig.Rank = ADC_REGULAR_RANK_1;
  sConfig.SamplingTime = ADC_SAMPLETIME_2CYCLES_5;
  sConfig.SingleDiff = ADC_SINGLE_ENDED;
  sConfig.OffsetNumber = ADC_OFFSET_NONE;
  sConfig.Offset = 0;
  if (HAL_ADC_ConfigChannel(&hadc2, &sConfig) != HAL_OK)
  {
    Error_Handler();
  }

  /** Configure Injected Channel
  */
  sConfigInjected.InjectedChannel = ADC_CHANNEL_4;
  sConfigInjected.InjectedRank = ADC_INJECTED_RANK_1;
  sConfigInjected.InjectedSamplingTime = ADC_SAMPLETIME_2CYCLES_5;
  sConfigInjected.InjectedSingleDiff = ADC_SINGLE_ENDED;
  sConfigInjected.InjectedOffsetNumber = ADC_OFFSET_NONE;
  sConfigInjected.InjectedOffset = 0;
  sConfigInjected.InjectedNbrOfConversion = 1;
  sConfigInjected.InjectedDiscontinuousConvMode = DISABLE;
  sConfigInjected.AutoInjectedConv = DISABLE;
  sConfigInjected.QueueInjectedContext = DISABLE;
  sConfigInjected.ExternalTrigInjecConv = ADC_EXTERNALTRIGINJEC_T8_TRGO;
  sConfigInjected.ExternalTrigInjecConvEdge = ADC_EXTERNALTRIGINJECCONV_EDGE_RISING;
  sConfigInjected.InjecOversamplingMode = DISABLE;
  if (HAL_ADCEx_InjectedConfigChannel(&hadc2, &sConfigInjected) != HAL_OK)
  {
    Error_Handler();
  }

}

static void MX_ADC3_Init(void)
{

  ADC_MultiModeTypeDef multimode = {0};
  ADC_ChannelConfTypeDef sConfig = {0};
  ADC_InjectionConfTypeDef sConfigInjected = {0};

  /** Common config
  */
  hadc3.Instance = ADC3;
  hadc3.Init.ClockPrescaler = ADC_CLOCK_SYNC_PCLK_DIV4;
  hadc3.Init.Resolution = ADC_RESOLUTION_12B;
  hadc3.Init.DataAlign = ADC_DATAALIGN_RIGHT;
  hadc3.Init.GainCompensation = 0;
  hadc3.Init.ScanConvMode = ADC_SCAN_DISABLE;
  hadc3.Init.EOCSelection = ADC_EOC_SINGLE_CONV;
  hadc3.Init.LowPowerAutoWait = DISABLE;
  hadc3.Init.ContinuousConvMode = DISABLE;
  hadc3.Init.NbrOfConversion = 1;
  hadc3.Init.DiscontinuousConvMode = DISABLE;
  hadc3.Init.ExternalTrigConv = ADC_SOFTWARE_START;
  hadc3.Init.ExternalTrigConvEdge = ADC_EXTERNALTRIGCONVEDGE_NONE;
  hadc3.Init.DMAContinuousRequests = DISABLE;
  hadc3.Init.Overrun = ADC_OVR_DATA_PRESERVED;
  hadc3.Init.OversamplingMode = DISABLE;
  if (HAL_ADC_Init(&hadc3) != HAL_OK)
  {
    Error_Handler();
  }

  /** Configure the ADC multi-mode
  */
  multimode.Mode = ADC_MODE_INDEPENDENT;
  if (HAL_ADCEx_MultiModeConfigChannel(&hadc3, &multimode) != HAL_OK)
  {
    Error_Handler();
  }

  /** Configure Regular Channel
  */
  sConfig.Channel = ADC_CHANNEL_9;
  sConfig.Rank = ADC_REGULAR_RANK_1;
  sConfig.SamplingTime = ADC_SAMPLETIME_2CYCLES_5;
  sConfig.SingleDiff = ADC_SINGLE_ENDED;
  sConfig.OffsetNumber = ADC_OFFSET_NONE;
  sConfig.Offset = 0;
  if (HAL_ADC_ConfigChannel(&hadc3, &sConfig) != HAL_OK)
  {
    Error_Handler();
  }

  /** Configure Injected Channel
  */
  sConfigInjected.InjectedChannel = ADC_CHANNEL_9;
  sConfigInjected.InjectedRank = ADC_INJECTED_RANK_1;
  sConfigInjected.InjectedSamplingTime = ADC_SAMPLETIME_2CYCLES_5;
  sConfigInjected.InjectedSingleDiff = ADC_SINGLE_ENDED;
  sConfigInjected.InjectedOffsetNumber = ADC_OFFSET_NONE;
  sConfigInjected.InjectedOffset = 0;
  sConfigInjected.InjectedNbrOfConversion = 1;
  sConfigInjected.InjectedDiscontinuousConvMode = DISABLE;
  sConfigInjected.AutoInjectedConv = DISABLE;
  sConfigInjected.QueueInjectedContext = DISABLE;
  sConfigInjected.ExternalTrigInjecConv = ADC_EXTERNALTRIGINJEC_T8_TRGO;
  sConfigInjected.ExternalTrigInjecConvEdge = ADC_EXTERNALTRIGINJECCONV_EDGE_RISING;
  sConfigInjected.InjecOversamplingMode = DISABLE;
  if (HAL_ADCEx_InjectedConfigChannel(&hadc3, &sConfigInjected) != HAL_OK)
  {
    Error_Handler();
  }

}

static void MX_COMP1_Init(void)
{

  hcomp1.Instance = COMP1;
  hcomp1.Init.InputPlus = COMP_INPUT_PLUS_IO2;
  hcomp1.Init.InputMinus = COMP_INPUT_MINUS_DAC3_CH1;
  hcomp1.Init.OutputPol = COMP_OUTPUTPOL_NONINVERTED;
  hcomp1.Init.Hysteresis = COMP_HYSTERESIS_NONE;
  hcomp1.Init.BlankingSrce = COMP_BLANKINGSRC_NONE;
  hcomp1.Init.TriggerMode = COMP_TRIGGERMODE_NONE;
  if (HAL_COMP_Init(&hcomp1) != HAL_OK)
  {
    Error_Handler();
  }

}

static void MX_COMP2_Init(void)
{

  hcomp2.Instance = COMP2;
  hcomp2.Init.InputPlus = COMP_INPUT_PLUS_IO2;
  hcomp2.Init.InputMinus = COMP_INPUT_MINUS_DAC3_CH2;
  hcomp2.Init.OutputPol = COMP_OUTPUTPOL_NONINVERTED;
  hcomp2.Init.Hysteresis = COMP_HYSTERESIS_NONE;
  hcomp2.Init.BlankingSrce = COMP_BLANKINGSRC_NONE;
  hcomp2.Init.TriggerMode = COMP_TRIGGERMODE_NONE;
  if (HAL_COMP_Init(&hcomp2) != HAL_OK)
  {
    Error_Handler();
  }

}

static void MX_COMP3_Init(void)
{

  hcomp3.Instance = COMP3;
  hcomp3.Init.InputPlus = COMP_INPUT_PLUS_IO2;
  hcomp3.Init.InputMinus = COMP_INPUT_MINUS_DAC3_CH1;
  hcomp3.Init.OutputPol = COMP_OUTPUTPOL_NONINVERTED;
  hcomp3.Init.Hysteresis = COMP_HYSTERESIS_NONE;
  hcomp3.Init.BlankingSrce = COMP_BLANKINGSRC_NONE;
  hcomp3.Init.TriggerMode = COMP_TRIGGERMODE_NONE;
  if (HAL_COMP_Init(&hcomp3) != HAL_OK)
  {
    Error_Handler();
  }

}

static void MX_COMP4_Init(void)
{

  hcomp4.Instance = COMP4;
  hcomp4.Init.InputPlus = COMP_INPUT_PLUS_IO2;
  hcomp4.Init.InputMinus = COMP_INPUT_MINUS_DAC3_CH2;
  hcomp4.Init.OutputPol = COMP_OUTPUTPOL_NONINVERTED;
  hcomp4.Init.Hysteresis = COMP_HYSTERESIS_NONE;
  hcomp4.Init.BlankingSrce = COMP_BLANKINGSRC_NONE;
  hcomp4.Init.TriggerMode = COMP_TRIGGERMODE_NONE;
  if (HAL_COMP_Init(&hcomp4) != HAL_OK)
  {
    Error_Handler();
  }

}

static void MX_COMP5_Init(void)
{

  hcomp5.Instance = COMP5;
  hcomp5.Init.InputPlus = COMP_INPUT_PLUS_IO2;
  hcomp5.Init.InputMinus = COMP_INPUT_MINUS_DAC4_CH1;
  hcomp5.Init.OutputPol = COMP_OUTPUTPOL_NONINVERTED;
  hcomp5.Init.Hysteresis = COMP_HYSTERESIS_NONE;
  hcomp5.Init.BlankingSrce = COMP_BLANKINGSRC_NONE;
  hcomp5.Init.TriggerMode = COMP_TRIGGERMODE_NONE;
  if (HAL_COMP_Init(&hcomp5) != HAL_OK)
  {
    Error_Handler();
  }

}

static void MX_COMP6_Init(void)
{

  hcomp6.Instance = COMP6;
  hcomp6.Init.InputPlus = COMP_INPUT_PLUS_IO1;
  hcomp6.Init.InputMinus = COMP_INPUT_MINUS_DAC4_CH2;
  hcomp6.Init.OutputPol = COMP_OUTPUTPOL_NONINVERTED;
  hcomp6.Init.Hysteresis = COMP_HYSTERESIS_NONE;
  hcomp6.Init.BlankingSrce = COMP_BLANKINGSRC_NONE;
  hcomp6.Init.TriggerMode = COMP_TRIGGERMODE_NONE;
  if (HAL_COMP_Init(&hcomp6) != HAL_OK)
  {
    Error_Handler();
  }

}

static void MX_CRC_Init(void)
{

  hcrc.Instance = CRC;
  hcrc.Init.DefaultPolynomialUse = DEFAULT_POLYNOMIAL_ENABLE;
  hcrc.Init.DefaultInitValueUse = DEFAULT_INIT_VALUE_ENABLE;
  hcrc.Init.InputDataInversionMode = CRC_INPUTDATA_INVERSION_NONE;
  hcrc.Init.OutputDataInversionMode = CRC_OUTPUTDATA_INVERSION_DISABLE;
  hcrc.InputDataFormat = CRC_INPUTDATA_FORMAT_BYTES;
  if (HAL_CRC_Init(&hcrc) != HAL_OK)
  {
    Error_Handler();
  }

}

static void MX_DAC1_Init(void)
{

  DAC_ChannelConfTypeDef sConfig = {0};

  /** DAC Initialization
  */
  hdac1.Instance = DAC1;
  if (HAL_DAC_Init(&hdac1) != HAL_OK)
  {
    Error_Handler();
  }

  /** DAC channel OUT1 config
  */
  sConfig.DAC_HighFrequency = DAC_HIGH_FREQUENCY_INTERFACE_MODE_AUTOMATIC;
  sConfig.DAC_DMADoubleDataMode = DISABLE;
  sConfig.DAC_SignedFormat = DISABLE;
  sConfig.DAC_SampleAndHold = DAC_SAMPLEANDHOLD_DISABLE;
  sConfig.DAC_Trigger = DAC_TRIGGER_NONE;
  sConfig.DAC_Trigger2 = DAC_TRIGGER_NONE;
  sConfig.DAC_OutputBuffer = DAC_OUTPUTBUFFER_ENABLE;
  sConfig.DAC_ConnectOnChipPeripheral = DAC_CHIPCONNECT_EXTERNAL;
  sConfig.DAC_UserTrimming = DAC_TRIMMING_FACTORY;
  if (HAL_DAC_ConfigChannel(&hdac1, &sConfig, DAC_CHANNEL_1) != HAL_OK)
  {
    Error_Handler();
  }

  /** DAC channel OUT2 config
  */
  if (HAL_DAC_ConfigChannel(&hdac1, &sConfig, DAC_CHANNEL_2) != HAL_OK)
  {
    Error_Handler();
  }

}

static void MX_DAC2_Init(void)
{

  DAC_ChannelConfTypeDef sConfig = {0};

  /** DAC Initialization
  */
  hdac2.Instance = DAC2;
  if (HAL_DAC_Init(&hdac2) != HAL_OK)
  {
    Error_Handler();
  }

  /** DAC channel OUT1 config
  */
  sConfig.DAC_HighFrequency = DAC_HIGH_FREQUENCY_INTERFACE_MODE_AUTOMATIC;
  sConfig.DAC_DMADoubleDataMode = DISABLE;
  sConfig.DAC_SignedFormat = DISABLE;
  sConfig.DAC_SampleAndHold = DAC_SAMPLEANDHOLD_DISABLE;
  sConfig.DAC_Trigger = DAC_TRIGGER_NONE;
  sConfig.DAC_Trigger2 = DAC_TRIGGER_NONE;
  sConfig.DAC_OutputBuffer = DAC_OUTPUTBUFFER_DISABLE;
  sConfig.DAC_ConnectOnChipPeripheral = DAC_CHIPCONNECT_INTERNAL;
  sConfig.DAC_UserTrimming = DAC_TRIMMING_FACTORY;
  if (HAL_DAC_ConfigChannel(&hdac2, &sConfig, DAC_CHANNEL_1) != HAL_OK)
  {
    Error_Handler();
  }

}

static void MX_DAC3_Init(void)
{

  DAC_ChannelConfTypeDef sConfig = {0};

  /** DAC Initialization
  */
  hdac3.Instance = DAC3;
  if (HAL_DAC_Init(&hdac3) != HAL_OK)
  {
    Error_Handler();
  }

  /** DAC channel OUT1 config
  */
  sConfig.DAC_HighFrequency = DAC_HIGH_FREQUENCY_INTERFACE_MODE_AUTOMATIC;
  sConfig.DAC_DMADoubleDataMode = DISABLE;
  sConfig.DAC_SignedFormat = DISABLE;
  sConfig.DAC_SampleAndHold = DAC_SAMPLEANDHOLD_DISABLE;
  sConfig.DAC_Trigger = DAC_TRIGGER_NONE;
  sConfig.DAC_Trigger2 = DAC_TRIGGER_NONE;
  sConfig.DAC_OutputBuffer = DAC_OUTPUTBUFFER_DISABLE;
  sConfig.DAC_ConnectOnChipPeripheral = DAC_CHIPCONNECT_INTERNAL;
  sConfig.DAC_UserTrimming = DAC_TRIMMING_FACTORY;
  if (HAL_DAC_ConfigChannel(&hdac3, &sConfig, DAC_CHANNEL_1) != HAL_OK)
  {
    Error_Handler();
  }

  /** DAC channel OUT2 config
  */
  if (HAL_DAC_ConfigChannel(&hdac3, &sConfig, DAC_CHANNEL_2) != HAL_OK)
  {
    Error_Handler();
  }

}

static void MX_DAC4_Init(void)
{

  DAC_ChannelConfTypeDef sConfig = {0};

  /** DAC Initialization
  */
  hdac4.Instance = DAC4;
  if (HAL_DAC_Init(&hdac4) != HAL_OK)
  {
    Error_Handler();
  }

  /** DAC channel OUT1 config
  */
  sConfig.DAC_HighFrequency = DAC_HIGH_FREQUENCY_INTERFACE_MODE_AUTOMATIC;
  sConfig.DAC_DMADoubleDataMode = DISABLE;
  sConfig.DAC_SignedFormat = DISABLE;
  sConfig.DAC_SampleAndHold = DAC_SAMPLEANDHOLD_DISABLE;
  sConfig.DAC_Trigger = DAC_TRIGGER_NONE;
  sConfig.DAC_Trigger2 = DAC_TRIGGER_NONE;
  sConfig.DAC_OutputBuffer = DAC_OUTPUTBUFFER_DISABLE;
  sConfig.DAC_ConnectOnChipPeripheral = DAC_CHIPCONNECT_INTERNAL;
  sConfig.DAC_UserTrimming = DAC_TRIMMING_FACTORY;
  if (HAL_DAC_ConfigChannel(&hdac4, &sConfig, DAC_CHANNEL_1) != HAL_OK)
  {
    Error_Handler();
  }

  /** DAC channel OUT2 config
  */
  if (HAL_DAC_ConfigChannel(&hdac4, &sConfig, DAC_CHANNEL_2) != HAL_OK)
  {
    Error_Handler();
  }

}

static void MX_HRTIM1_Init(void)
{

  HRTIM_EventCfgTypeDef pEventCfg = {0};
  HRTIM_FaultBlankingCfgTypeDef pFaultBlkCfg = {0};
  HRTIM_FaultCfgTypeDef pFaultCfg = {0};
  HRTIM_TimeBaseCfgTypeDef pTimeBaseCfg = {0};
  HRTIM_TimerCfgTypeDef pTimerCfg = {0};
  HRTIM_TimerCtlTypeDef pTimerCtl = {0};
  HRTIM_OutputCfgTypeDef pOutputCfg = {0};

  hhrtim1.Instance = HRTIM1;
  hhrtim1.Init.HRTIMInterruptResquests = HRTIM_IT_NONE;
  hhrtim1.Init.SyncOptions = HRTIM_SYNCOPTION_NONE;
  if (HAL_HRTIM_Init(&hhrtim1) != HAL_OK)
  {
    Error_Handler();
  }
  if (HAL_HRTIM_DLLCalibrationStart(&hhrtim1, HRTIM_CALIBRATIONRATE_3) != HAL_OK)
  {
    Error_Handler();
  }
  if (HAL_HRTIM_PollForDLLCalibration(&hhrtim1, 10) != HAL_OK)
  {
    Error_Handler();
  }
  if (HAL_HRTIM_EventPrescalerConfig(&hhrtim1, HRTIM_EVENTPRESCALER_DIV1) != HAL_OK)
  {
    Error_Handler();
  }
  pEventCfg.Source = HRTIM_EEV1SRC_COMP2_OUT;
  pEventCfg.Polarity = HRTIM_EVENTPOLARITY_HIGH;
  pEventCfg.Sensitivity = HRTIM_EVENTSENSITIVITY_LEVEL;
  pEventCfg.FastMode = HRTIM_EVENTFASTMODE_DISABLE;
  if (HAL_HRTIM_EventConfig(&hhrtim1, HRTIM_EVENT_1, &pEventCfg) != HAL_OK)
  {
    Error_Handler();
  }
  pEventCfg.Source = HRTIM_EEV2SRC_COMP4_OUT;
  if (HAL_HRTIM_EventConfig(&hhrtim1, HRTIM_EVENT_2, &pEventCfg) != HAL_OK)
  {
    Error_Handler();
  }
  pEventCfg.Source = HRTIM_EEV4SRC_COMP1_OUT;
  if (HAL_HRTIM_EventConfig(&hhrtim1, HRTIM_EVENT_4, &pEventCfg) != HAL_OK)
  {
    Error_Handler();
  }
  pEventCfg.Source = HRTIM_EEV5SRC_COMP3_OUT;
  if (HAL_HRTIM_EventConfig(&hhrtim1, HRTIM_EVENT_5, &pEventCfg) != HAL_OK)
  {
    Error_Handler();
  }
  pEventCfg.Source = HRTIM_EEV9SRC_COMP5_OUT;
  pEventCfg.Filter = HRTIM_EVENTFILTER_NONE;
  if (HAL_HRTIM_EventConfig(&hhrtim1, HRTIM_EVENT_8, &pEventCfg) != HAL_OK)
  {
    Error_Handler();
  }
  pEventCfg.Source = HRTIM_EEV9SRC_GPIO;
  if (HAL_HRTIM_EventConfig(&hhrtim1, HRTIM_EVENT_9, &pEventCfg) != HAL_OK)
  {
    Error_Handler();
  }
  if (HAL_HRTIM_FaultPrescalerConfig(&hhrtim1, HRTIM_FAULTPRESCALER_DIV1) != HAL_OK)
  {
    Error_Handler();
  }
  pFaultBlkCfg.Threshold = 0;
  pFaultBlkCfg.ResetMode = HRTIM_FAULTCOUNTERRST_UNCONDITIONAL;
  pFaultBlkCfg.BlankingSource = HRTIM_FAULTBLANKINGMODE_RSTALIGNED;
  if (HAL_HRTIM_FaultCounterConfig(&hhrtim1, HRTIM_FAULT_3, &pFaultBlkCfg) != HAL_OK)
  {
    Error_Handler();
  }
  if (HAL_HRTIM_FaultBlankingConfigAndEnable(&hhrtim1, HRTIM_FAULT_3, &pFaultBlkCfg) != HAL_OK)
  {
    Error_Handler();
  }
  pFaultCfg.Source = HRTIM_FAULTSOURCE_DIGITALINPUT;
  pFaultCfg.Polarity = HRTIM_FAULTPOLARITY_HIGH;
  pFaultCfg.Filter = HRTIM_FAULTFILTER_NONE;
  pFaultCfg.Lock = HRTIM_FAULTLOCK_READWRITE;
  if (HAL_HRTIM_FaultConfig(&hhrtim1, HRTIM_FAULT_3, &pFaultCfg) != HAL_OK)
  {
    Error_Handler();
  }
  HAL_HRTIM_FaultModeCtl(&hhrtim1, HRTIM_FAULT_3, HRTIM_FAULTMODECTL_ENABLED);
  pTimeBaseCfg.Period = 0xFFDF;
  pTimeBaseCfg.RepetitionCounter = 0x00;
  pTimeBaseCfg.PrescalerRatio = HRTIM_PRESCALERRATIO_MUL32;
  pTimeBaseCfg.Mode = HRTIM_MODE_CONTINUOUS;
  if (HAL_HRTIM_TimeBaseConfig(&hhrtim1, HRTIM_TIMERINDEX_MASTER, &pTimeBaseCfg) != HAL_OK)
  {
    Error_Handler();
  }
  pTimerCfg.InterruptRequests = HRTIM_MASTER_IT_NONE;
  pTimerCfg.DMARequests = HRTIM_MASTER_DMA_NONE;
  pTimerCfg.DMASrcAddress = 0x0000;
  pTimerCfg.DMADstAddress = 0x0000;
  pTimerCfg.DMASize = 0x1;
  pTimerCfg.HalfModeEnable = HRTIM_HALFMODE_DISABLED;
  pTimerCfg.InterleavedMode = HRTIM_INTERLEAVED_MODE_DISABLED;
  pTimerCfg.StartOnSync = HRTIM_SYNCSTART_DISABLED;
  pTimerCfg.ResetOnSync = HRTIM_SYNCRESET_DISABLED;
  pTimerCfg.DACSynchro = HRTIM_DACSYNC_NONE;
  pTimerCfg.PreloadEnable = HRTIM_PRELOAD_DISABLED;
  pTimerCfg.UpdateGating = HRTIM_UPDATEGATING_INDEPENDENT;
  pTimerCfg.BurstMode = HRTIM_TIMERBURSTMODE_MAINTAINCLOCK;
  pTimerCfg.RepetitionUpdate = HRTIM_UPDATEONREPETITION_DISABLED;
  pTimerCfg.ReSyncUpdate = HRTIM_TIMERESYNC_UPDATE_UNCONDITIONAL;
  if (HAL_HRTIM_WaveformTimerConfig(&hhrtim1, HRTIM_TIMERINDEX_MASTER, &pTimerCfg) != HAL_OK)
  {
    Error_Handler();
  }
  if (HAL_HRTIM_TimeBaseConfig(&hhrtim1, HRTIM_TIMERINDEX_TIMER_A, &pTimeBaseCfg) != HAL_OK)
  {
    Error_Handler();
  }
  pTimerCtl.UpDownMode = HRTIM_TIMERUPDOWNMODE_UP;
  pTimerCtl.DualChannelDacEnable = HRTIM_TIMER_DCDE_DISABLED;
  if (HAL_HRTIM_WaveformTimerControl(&hhrtim1, HRTIM_TIMERINDEX_TIMER_A, &pTimerCtl) != HAL_OK)
  {
    Error_Handler();
  }
  pTimerCfg.InterruptRequests = HRTIM_TIM_IT_NONE;
  pTimerCfg.DMARequests = HRTIM_TIM_DMA_NONE;
  pTimerCfg.PushPull = HRTIM_TIMPUSHPULLMODE_DISABLED;
  pTimerCfg.FaultEnable = HRTIM_TIMFAULTENABLE_NONE;
  pTimerCfg.FaultLock = HRTIM_TIMFAULTLOCK_READWRITE;
  pTimerCfg.DeadTimeInsertion = HRTIM_TIMDEADTIMEINSERTION_DISABLED;
  pTimerCfg.DelayedProtectionMode = HRTIM_TIMER_A_B_C_DELAYEDPROTECTION_DISABLED;
  pTimerCfg.UpdateTrigger = HRTIM_TIMUPDATETRIGGER_NONE;
  pTimerCfg.ResetTrigger = HRTIM_TIMRESETTRIGGER_NONE;
  pTimerCfg.ResetUpdate = HRTIM_TIMUPDATEONRESET_DISABLED;
  if (HAL_HRTIM_WaveformTimerConfig(&hhrtim1, HRTIM_TIMERINDEX_TIMER_A, &pTimerCfg) != HAL_OK)
  {
    Error_Handler();
  }
  if (HAL_HRTIM_WaveformTimerConfig(&hhrtim1, HRTIM_TIMERINDEX_TIMER_B, &pTimerCfg) != HAL_OK)
  {
    Error_Handler();
  }
  if (HAL_HRTIM_WaveformTimerConfig(&hhrtim1, HRTIM_TIMERINDEX_TIMER_C, &pTimerCfg) != HAL_OK)
  {
    Error_Handler();
  }
  pTimerCfg.DelayedProtectionMode = HRTIM_TIMER_D_E_DELAYEDPROTECTION_DISABLED;
  if (HAL_HRTIM_WaveformTimerConfig(&hhrtim1, HRTIM_TIMERINDEX_TIMER_D, &pTimerCfg) != HAL_OK)
  {
    Error_Handler();
  }
  if (HAL_HRTIM_WaveformTimerConfig(&hhrtim1, HRTIM_TIMERINDEX_TIMER_E, &pTimerCfg) != HAL_OK)
  {
    Error_Handler();
  }
  pTimerCfg.DelayedProtectionMode = HRTIM_TIMER_F_DELAYEDPROTECTION_DISABLED;
  if (HAL_HRTIM_WaveformTimerConfig(&hhrtim1, HRTIM_TIMERINDEX_TIMER_F, &pTimerCfg) != HAL_OK)
  {
    Error_Handler();
  }
  pOutputCfg.Polarity = HRTIM_OUTPUTPOLARITY_HIGH;
  pOutputCfg.SetSource = HRTIM_OUTPUTSET_NONE;
  pOutputCfg.ResetSource = HRTIM_OUTPUTRESET_NONE;
  pOutputCfg.IdleMode = HRTIM_OUTPUTIDLEMODE_NONE;
  pOutputCfg.IdleLevel = HRTIM_OUTPUTIDLELEVEL_INACTIVE;
  pOutputCfg.FaultLevel = HRTIM_OUTPUTFAULTLEVEL_NONE;
  pOutputCfg.ChopperModeEnable = HRTIM_OUTPUTCHOPPERMODE_DISABLED;
  pOutputCfg.BurstModeEntryDelayed = HRTIM_OUTPUTBURSTMODEENTRY_REGULAR;
  if (HAL_HRTIM_WaveformOutputConfig(&hhrtim1, HRTIM_TIMERINDEX_TIMER_A, HRTIM_OUTPUT_TA2, &pOutputCfg) != HAL_OK)
  {
    Error_Handler();
  }
  if (HAL_HRTIM_WaveformOutputConfig(&hhrtim1, HRTIM_TIMERINDEX_TIMER_C, HRTIM_OUTPUT_TC2, &pOutputCfg) != HAL_OK)
  {
    Error_Handler();
  }
  if (HAL_HRTIM_WaveformOutputConfig(&hhrtim1, HRTIM_TIMERINDEX_TIMER_D, HRTIM_OUTPUT_TD2, &pOutputCfg) != HAL_OK)
  {
    Error_Handler();
  }
  if (HAL_HRTIM_WaveformOutputConfig(&hhrtim1, HRTIM_TIMERINDEX_TIMER_E, HRTIM_OUTPUT_TE2, &pOutputCfg) != HAL_OK)
  {
    Error_Handler();
  }
  if (HAL_HRTIM_WaveformOutputConfig(&hhrtim1, HRTIM_TIMERINDEX_TIMER_F, HRTIM_OUTPUT_TF2, &pOutputCfg) != HAL_OK)
  {
    Error_Handler();
  }
  if (HAL_HRTIM_TimeBaseConfig(&hhrtim1, HRTIM_TIMERINDEX_TIMER_B, &pTimeBaseCfg) != HAL_OK)
  {
    Error_Handler();
  }
  if (HAL_HRTIM_WaveformTimerControl(&hhrtim1, HRTIM_TIMERINDEX_TIMER_B, &pTimerCtl) != HAL_OK)
  {
    Error_Handler();
  }
  if (HAL_HRTIM_WaveformOutputConfig(&hhrtim1, HRTIM_TIMERINDEX_TIMER_B, HRTIM_OUTPUT_TB1, &pOutputCfg) != HAL_OK)
  {
    Error_Handler();
  }
  if (HAL_HRTIM_WaveformOutputConfig(&hhrtim1, HRTIM_TIMERINDEX_TIMER_C, HRTIM_OUTPUT_TC1, &pOutputCfg) != HAL_OK)
  {
    Error_Handler();
  }
  if (HAL_HRTIM_WaveformOutputConfig(&hhrtim1, HRTIM_TIMERINDEX_TIMER_D, HRTIM_OUTPUT_TD1, &pOutputCfg) != HAL_OK)
  {
    Error_Handler();
  }
  if (HAL_HRTIM_WaveformOutputConfig(&hhrtim1, HRTIM_TIMERINDEX_TIMER_E, HRTIM_OUTPUT_TE1, &pOutputCfg) != HAL_OK)
  {
    Error_Handler();
  }
  if (HAL_HRTIM_WaveformOutputConfig(&hhrtim1, HRTIM_TIMERINDEX_TIMER_F, HRTIM_OUTPUT_TF1, &pOutputCfg) != HAL_OK)
  {
    Error_Handler();
  }
  if (HAL_HRTIM_TimeBaseConfig(&hhrtim1, HRTIM_TIMERINDEX_TIMER_C, &pTimeBaseCfg) != HAL_OK)
  {
    Error_Handler();
  }
  if (HAL_HRTIM_WaveformTimerControl(&hhrtim1, HRTIM_TIMERINDEX_TIMER_C, &pTimerCtl) != HAL_OK)
  {
    Error_Handler();
  }
  if (HAL_HRTIM_TimeBaseConfig(&hhrtim1, HRTIM_TIMERINDEX_TIMER_D, &pTimeBaseCfg) != HAL_OK)
  {
    Error_Handler();
  }
  if (HAL_HRTIM_WaveformTimerControl(&hhrtim1, HRTIM_TIMERINDEX_TIMER_D, &pTimerCtl) != HAL_OK)
  {
    Error_Handler();
  }
  if (HAL_HRTIM_TimeBaseConfig(&hhrtim1, HRTIM_TIMERINDEX_TIMER_E, &pTimeBaseCfg) != HAL_OK)
  {
    Error_Handler();
  }
  if (HAL_HRTIM_WaveformTimerControl(&hhrtim1, HRTIM_TIMERINDEX_TIMER_E, &pTimerCtl) != HAL_OK)
  {
    Error_Handler();
  }
  if (HAL_HRTIM_TimeBaseConfig(&hhrtim1, HRTIM_TIMERINDEX_TIMER_F, &pTimeBaseCfg) != HAL_OK)
  {
    Error_Handler();
  }
  if (HAL_HRTIM_WaveformTimerControl(&hhrtim1, HRTIM_TIMERINDEX_TIMER_F, &pTimerCtl) != HAL_OK)
  {
    Error_Handler();
  }
  HAL_HRTIM_MspPostInit(&hhrtim1);

}

static void MX_I2C1_Init(void)
{

  hi2c1.Instance = I2C1;
  hi2c1.Init.Timing = 0x40B285C2;
  hi2c1.Init.OwnAddress1 = 0;
  hi2c1.Init.AddressingMode = I2C_ADDRESSINGMODE_7BIT;
  hi2c1.Init.DualAddressMode = I2C_DUALADDRESS_DISABLE;
  hi2c1.Init.OwnAddress2 = 0;
  hi2c1.Init.OwnAddress2Masks = I2C_OA2_NOMASK;
  hi2c1.Init.GeneralCallMode = I2C_GENERALCALL_DISABLE;
  hi2c1.Init.NoStretchMode = I2C_NOSTRETCH_DISABLE;
  if (HAL_I2C_Init(&hi2c1) != HAL_OK)
  {
    Error_Handler();
  }

  /** Configure Analogue filter
  */
  if (HAL_I2CEx_ConfigAnalogFilter(&hi2c1, I2C_ANALOGFILTER_ENABLE) != HAL_OK)
  {
    Error_Handler();
  }

  /** Configure Digital filter
  */
  if (HAL_I2CEx_ConfigDigitalFilter(&hi2c1, 0) != HAL_OK)
  {
    Error_Handler();
  }

}

static void MX_I2C3_Init(void)
{

  hi2c3.Instance = I2C3;
  hi2c3.Init.Timing = 0x40B285C2;
  hi2c3.Init.OwnAddress1 = 0;
  hi2c3.Init.AddressingMode = I2C_ADDRESSINGMODE_7BIT;
  hi2c3.Init.DualAddressMode = I2C_DUALADDRESS_DISABLE;
  hi2c3.Init.OwnAddress2 = 0;
  hi2c3.Init.OwnAddress2Masks = I2C_OA2_NOMASK;
  hi2c3.Init.GeneralCallMode = I2C_GENERALCALL_DISABLE;
  hi2c3.Init.NoStretchMode = I2C_NOSTRETCH_DISABLE;
  if (HAL_I2C_Init(&hi2c3) != HAL_OK)
  {
    Error_Handler();
  }

  /** Configure Analogue filter
  */
  if (HAL_I2CEx_ConfigAnalogFilter(&hi2c3, I2C_ANALOGFILTER_ENABLE) != HAL_OK)
  {
    Error_Handler();
  }

  /** Configure Digital filter
  */
  if (HAL_I2CEx_ConfigDigitalFilter(&hi2c3, 0) != HAL_OK)
  {
    Error_Handler();
  }

}

static void MX_QUADSPI1_Init(void)
{

  /* QUADSPI1 parameter configuration*/
  hqspi1.Instance = QUADSPI;
  hqspi1.Init.ClockPrescaler = 255;
  hqspi1.Init.FifoThreshold = 1;
  hqspi1.Init.SampleShifting = QSPI_SAMPLE_SHIFTING_NONE;
  hqspi1.Init.FlashSize = 1;
  hqspi1.Init.ChipSelectHighTime = QSPI_CS_HIGH_TIME_1_CYCLE;
  hqspi1.Init.ClockMode = QSPI_CLOCK_MODE_0;
  hqspi1.Init.DualFlash = QSPI_DUALFLASH_ENABLE;
  if (HAL_QSPI_Init(&hqspi1) != HAL_OK)
  {
    Error_Handler();
  }

}

static void MX_SPI3_Init(void)
{

  /* SPI3 parameter configuration*/
  hspi3.Instance = SPI3;
  hspi3.Init.Mode = SPI_MODE_MASTER;
  hspi3.Init.Direction = SPI_DIRECTION_2LINES;
  hspi3.Init.DataSize = SPI_DATASIZE_4BIT;
  hspi3.Init.CLKPolarity = SPI_POLARITY_LOW;
  hspi3.Init.CLKPhase = SPI_PHASE_1EDGE;
  hspi3.Init.NSS = SPI_NSS_HARD_OUTPUT;
  hspi3.Init.BaudRatePrescaler = SPI_BAUDRATEPRESCALER_64;
  hspi3.Init.FirstBit = SPI_FIRSTBIT_MSB;
  hspi3.Init.TIMode = SPI_TIMODE_DISABLE;
  hspi3.Init.CRCCalculation = SPI_CRCCALCULATION_DISABLE;
  hspi3.Init.CRCPolynomial = 7;
  hspi3.Init.CRCLength = SPI_CRC_LENGTH_DATASIZE;
  hspi3.Init.NSSPMode = SPI_NSS_PULSE_ENABLE;
  if (HAL_SPI_Init(&hspi3) != HAL_OK)
  {
    Error_Handler();
  }

}

static void MX_SPI4_Init(void)
{

  /* SPI4 parameter configuration*/
  hspi4.Instance = SPI4;
  hspi4.Init.Mode = SPI_MODE_MASTER;
  hspi4.Init.Direction = SPI_DIRECTION_2LINES;
  hspi4.Init.DataSize = SPI_DATASIZE_4BIT;
  hspi4.Init.CLKPolarity = SPI_POLARITY_LOW;
  hspi4.Init.CLKPhase = SPI_PHASE_1EDGE;
  hspi4.Init.NSS = SPI_NSS_HARD_OUTPUT;
  hspi4.Init.BaudRatePrescaler = SPI_BAUDRATEPRESCALER_32;
  hspi4.Init.FirstBit = SPI_FIRSTBIT_MSB;
  hspi4.Init.TIMode = SPI_TIMODE_DISABLE;
  hspi4.Init.CRCCalculation = SPI_CRCCALCULATION_DISABLE;
  hspi4.Init.CRCPolynomial = 7;
  hspi4.Init.CRCLength = SPI_CRC_LENGTH_DATASIZE;
  hspi4.Init.NSSPMode = SPI_NSS_PULSE_ENABLE;
  if (HAL_SPI_Init(&hspi4) != HAL_OK)
  {
    Error_Handler();
  }

}

static void MX_TIM1_Init(void)
{

  TIM_ClockConfigTypeDef sClockSourceConfig = {0};
  TIM_SlaveConfigTypeDef sSlaveConfig = {0};
  TIM_MasterConfigTypeDef sMasterConfig = {0};
  TIM_IC_InitTypeDef sConfigIC = {0};

  htim1.Instance = TIM1;
  htim1.Init.Prescaler = 0;
  htim1.Init.CounterMode = TIM_COUNTERMODE_UP;
  htim1.Init.Period = 65535;
  htim1.Init.ClockDivision = TIM_CLOCKDIVISION_DIV1;
  htim1.Init.RepetitionCounter = 0;
  htim1.Init.AutoReloadPreload = TIM_AUTORELOAD_PRELOAD_DISABLE;
  if (HAL_TIM_Base_Init(&htim1) != HAL_OK)
  {
    Error_Handler();
  }
  sClockSourceConfig.ClockSource = TIM_CLOCKSOURCE_INTERNAL;
  if (HAL_TIM_ConfigClockSource(&htim1, &sClockSourceConfig) != HAL_OK)
  {
    Error_Handler();
  }
  if (HAL_TIM_IC_Init(&htim1) != HAL_OK)
  {
    Error_Handler();
  }
  sSlaveConfig.SlaveMode = TIM_SLAVEMODE_TRIGGER;
  sSlaveConfig.InputTrigger = TIM_TS_TI1F_ED;
  sSlaveConfig.TriggerFilter = 0;
  if (HAL_TIM_SlaveConfigSynchro(&htim1, &sSlaveConfig) != HAL_OK)
  {
    Error_Handler();
  }
  sMasterConfig.MasterOutputTrigger = TIM_TRGO_RESET;
  sMasterConfig.MasterOutputTrigger2 = TIM_TRGO2_RESET;
  sMasterConfig.MasterSlaveMode = TIM_MASTERSLAVEMODE_DISABLE;
  if (HAL_TIMEx_MasterConfigSynchronization(&htim1, &sMasterConfig) != HAL_OK)
  {
    Error_Handler();
  }
  sConfigIC.ICPolarity = TIM_INPUTCHANNELPOLARITY_RISING;
  sConfigIC.ICSelection = TIM_ICSELECTION_TRC;
  sConfigIC.ICPrescaler = TIM_ICPSC_DIV1;
  sConfigIC.ICFilter = 0;
  if (HAL_TIM_IC_ConfigChannel(&htim1, &sConfigIC, TIM_CHANNEL_1) != HAL_OK)
  {
    Error_Handler();
  }

}

static void MX_TIM2_Init(void)
{

  TIM_ClockConfigTypeDef sClockSourceConfig = {0};
  TIM_MasterConfigTypeDef sMasterConfig = {0};
  TIM_OC_InitTypeDef sConfigOC = {0};

  htim2.Instance = TIM2;
  htim2.Init.Prescaler = 0;
  htim2.Init.CounterMode = TIM_COUNTERMODE_UP;
  htim2.Init.Period = 4294967295;
  htim2.Init.ClockDivision = TIM_CLOCKDIVISION_DIV1;
  htim2.Init.AutoReloadPreload = TIM_AUTORELOAD_PRELOAD_DISABLE;
  if (HAL_TIM_Base_Init(&htim2) != HAL_OK)
  {
    Error_Handler();
  }
  sClockSourceConfig.ClockSource = TIM_CLOCKSOURCE_INTERNAL;
  if (HAL_TIM_ConfigClockSource(&htim2, &sClockSourceConfig) != HAL_OK)
  {
    Error_Handler();
  }
  if (HAL_TIM_PWM_Init(&htim2) != HAL_OK)
  {
    Error_Handler();
  }
  sMasterConfig.MasterOutputTrigger = TIM_TRGO_RESET;
  sMasterConfig.MasterSlaveMode = TIM_MASTERSLAVEMODE_DISABLE;
  if (HAL_TIMEx_MasterConfigSynchronization(&htim2, &sMasterConfig) != HAL_OK)
  {
    Error_Handler();
  }
  sConfigOC.OCMode = TIM_OCMODE_PWM1;
  sConfigOC.Pulse = 0;
  sConfigOC.OCPolarity = TIM_OCPOLARITY_HIGH;
  sConfigOC.OCFastMode = TIM_OCFAST_DISABLE;
  if (HAL_TIM_PWM_ConfigChannel(&htim2, &sConfigOC, TIM_CHANNEL_1) != HAL_OK)
  {
    Error_Handler();
  }
  if (HAL_TIM_PWM_ConfigChannel(&htim2, &sConfigOC, TIM_CHANNEL_2) != HAL_OK)
  {
    Error_Handler();
  }
  HAL_TIM_MspPostInit(&htim2);

}

static void MX_TIM3_Init(void)
{

  TIM_ClockConfigTypeDef sClockSourceConfig = {0};
  TIM_MasterConfigTypeDef sMasterConfig = {0};
  TIM_OC_InitTypeDef sConfigOC = {0};

  htim3.Instance = TIM3;
  htim3.Init.Prescaler = 0;
  htim3.Init.CounterMode = TIM_COUNTERMODE_UP;
  htim3.Init.Period = 65535;
  htim3.Init.ClockDivision = TIM_CLOCKDIVISION_DIV1;
  htim3.Init.AutoReloadPreload = TIM_AUTORELOAD_PRELOAD_DISABLE;
  if (HAL_TIM_Base_Init(&htim3) != HAL_OK)
  {
    Error_Handler();
  }
  sClockSourceConfig.ClockSource = TIM_CLOCKSOURCE_INTERNAL;
  if (HAL_TIM_ConfigClockSource(&htim3, &sClockSourceConfig) != HAL_OK)
  {
    Error_Handler();
  }
  if (HAL_TIM_PWM_Init(&htim3) != HAL_OK)
  {
    Error_Handler();
  }
  sMasterConfig.MasterOutputTrigger = TIM_TRGO_RESET;
  sMasterConfig.MasterSlaveMode = TIM_MASTERSLAVEMODE_DISABLE;
  if (HAL_TIMEx_MasterConfigSynchronization(&htim3, &sMasterConfig) != HAL_OK)
  {
    Error_Handler();
  }
  sConfigOC.OCMode = TIM_OCMODE_PWM1;
  sConfigOC.Pulse = 0;
  sConfigOC.OCPolarity = TIM_OCPOLARITY_HIGH;
  sConfigOC.OCFastMode = TIM_OCFAST_DISABLE;
  if (HAL_TIM_PWM_ConfigChannel(&htim3, &sConfigOC, TIM_CHANNEL_1) != HAL_OK)
  {
    Error_Handler();
  }
  HAL_TIM_MspPostInit(&htim3);

}

static void MX_TIM5_Init(void)
{

  TIM_ClockConfigTypeDef sClockSourceConfig = {0};
  TIM_MasterConfigTypeDef sMasterConfig = {0};
  TIM_OC_InitTypeDef sConfigOC = {0};

  htim5.Instance = TIM5;
  htim5.Init.Prescaler = 0;
  htim5.Init.CounterMode = TIM_COUNTERMODE_UP;
  htim5.Init.Period = 4294967295;
  htim5.Init.ClockDivision = TIM_CLOCKDIVISION_DIV1;
  htim5.Init.AutoReloadPreload = TIM_AUTORELOAD_PRELOAD_DISABLE;
  if (HAL_TIM_Base_Init(&htim5) != HAL_OK)
  {
    Error_Handler();
  }
  sClockSourceConfig.ClockSource = TIM_CLOCKSOURCE_INTERNAL;
  if (HAL_TIM_ConfigClockSource(&htim5, &sClockSourceConfig) != HAL_OK)
  {
    Error_Handler();
  }
  if (HAL_TIM_PWM_Init(&htim5) != HAL_OK)
  {
    Error_Handler();
  }
  sMasterConfig.MasterOutputTrigger = TIM_TRGO_RESET;
  sMasterConfig.MasterSlaveMode = TIM_MASTERSLAVEMODE_DISABLE;
  if (HAL_TIMEx_MasterConfigSynchronization(&htim5, &sMasterConfig) != HAL_OK)
  {
    Error_Handler();
  }
  sConfigOC.OCMode = TIM_OCMODE_PWM1;
  sConfigOC.Pulse = 0;
  sConfigOC.OCPolarity = TIM_OCPOLARITY_HIGH;
  sConfigOC.OCFastMode = TIM_OCFAST_DISABLE;
  if (HAL_TIM_PWM_ConfigChannel(&htim5, &sConfigOC, TIM_CHANNEL_4) != HAL_OK)
  {
    Error_Handler();
  }
  HAL_TIM_MspPostInit(&htim5);

}

static void MX_TIM8_Init(void)
{

  TIM_ClockConfigTypeDef sClockSourceConfig = {0};
  TIM_MasterConfigTypeDef sMasterConfig = {0};

  htim8.Instance = TIM8;
  htim8.Init.Prescaler = 0;
  htim8.Init.CounterMode = TIM_COUNTERMODE_UP;
  htim8.Init.Period = 65535;
  htim8.Init.ClockDivision = TIM_CLOCKDIVISION_DIV1;
  htim8.Init.RepetitionCounter = 0;
  htim8.Init.AutoReloadPreload = TIM_AUTORELOAD_PRELOAD_DISABLE;
  if (HAL_TIM_Base_Init(&htim8) != HAL_OK)
  {
    Error_Handler();
  }
  sClockSourceConfig.ClockSource = TIM_CLOCKSOURCE_INTERNAL;
  if (HAL_TIM_ConfigClockSource(&htim8, &sClockSourceConfig) != HAL_OK)
  {
    Error_Handler();
  }
  sMasterConfig.MasterOutputTrigger = TIM_TRGO_UPDATE;
  sMasterConfig.MasterOutputTrigger2 = TIM_TRGO2_RESET;
  sMasterConfig.MasterSlaveMode = TIM_MASTERSLAVEMODE_DISABLE;
  if (HAL_TIMEx_MasterConfigSynchronization(&htim8, &sMasterConfig) != HAL_OK)
  {
    Error_Handler();
  }

}

static void MX_TIM20_Init(void)
{

  TIM_Encoder_InitTypeDef sConfig = {0};
  TIM_MasterConfigTypeDef sMasterConfig = {0};

  htim20.Instance = TIM20;
  htim20.Init.Prescaler = 0;
  htim20.Init.CounterMode = TIM_COUNTERMODE_UP;
  htim20.Init.Period = 65535;
  htim20.Init.ClockDivision = TIM_CLOCKDIVISION_DIV1;
  htim20.Init.RepetitionCounter = 0;
  htim20.Init.AutoReloadPreload = TIM_AUTORELOAD_PRELOAD_DISABLE;
  sConfig.EncoderMode = TIM_ENCODERMODE_TI1;
  sConfig.IC1Polarity = TIM_ICPOLARITY_RISING;
  sConfig.IC1Selection = TIM_ICSELECTION_DIRECTTI;
  sConfig.IC1Prescaler = TIM_ICPSC_DIV1;
  sConfig.IC1Filter = 0;
  sConfig.IC2Polarity = TIM_ICPOLARITY_RISING;
  sConfig.IC2Selection = TIM_ICSELECTION_DIRECTTI;
  sConfig.IC2Prescaler = TIM_ICPSC_DIV1;
  sConfig.IC2Filter = 0;
  if (HAL_TIM_Encoder_Init(&htim20, &sConfig) != HAL_OK)
  {
    Error_Handler();
  }
  sMasterConfig.MasterOutputTrigger = TIM_TRGO_RESET;
  sMasterConfig.MasterOutputTrigger2 = TIM_TRGO2_RESET;
  sMasterConfig.MasterSlaveMode = TIM_MASTERSLAVEMODE_DISABLE;
  if (HAL_TIMEx_MasterConfigSynchronization(&htim20, &sMasterConfig) != HAL_OK)
  {
    Error_Handler();
  }

}

static void MX_UCPD1_Init(void)
{

  LL_GPIO_InitTypeDef GPIO_InitStruct = {0};

  /* Peripheral clock enable */
  LL_APB1_GRP2_EnableClock(LL_APB1_GRP2_PERIPH_UCPD1);

  LL_AHB2_GRP1_EnableClock(LL_AHB2_GRP1_PERIPH_GPIOB);
  /**UCPD1 GPIO Configuration
  PB6   ------> UCPD1_CC1
  PB4   ------> UCPD1_CC2
  */
  GPIO_InitStruct.Pin = LL_GPIO_PIN_6;
  GPIO_InitStruct.Mode = LL_GPIO_MODE_ANALOG;
  GPIO_InitStruct.Pull = LL_GPIO_PULL_NO;
  LL_GPIO_Init(GPIOB, &GPIO_InitStruct);

  GPIO_InitStruct.Pin = LL_GPIO_PIN_4;
  GPIO_InitStruct.Mode = LL_GPIO_MODE_ANALOG;
  GPIO_InitStruct.Pull = LL_GPIO_PULL_NO;
  LL_GPIO_Init(GPIOB, &GPIO_InitStruct);

  /* UCPD1 DMA Init */

  /* UCPD1_RX Init */
  LL_DMA_SetPeriphRequest(DMA1, LL_DMA_CHANNEL_1, LL_DMAMUX_REQ_UCPD1_RX);

  LL_DMA_SetDataTransferDirection(DMA1, LL_DMA_CHANNEL_1, LL_DMA_DIRECTION_PERIPH_TO_MEMORY);

  LL_DMA_SetChannelPriorityLevel(DMA1, LL_DMA_CHANNEL_1, LL_DMA_PRIORITY_LOW);

  LL_DMA_SetMode(DMA1, LL_DMA_CHANNEL_1, LL_DMA_MODE_NORMAL);

  LL_DMA_SetPeriphIncMode(DMA1, LL_DMA_CHANNEL_1, LL_DMA_PERIPH_NOINCREMENT);

  LL_DMA_SetMemoryIncMode(DMA1, LL_DMA_CHANNEL_1, LL_DMA_MEMORY_INCREMENT);

  LL_DMA_SetPeriphSize(DMA1, LL_DMA_CHANNEL_1, LL_DMA_PDATAALIGN_BYTE);

  LL_DMA_SetMemorySize(DMA1, LL_DMA_CHANNEL_1, LL_DMA_MDATAALIGN_BYTE);

  /* UCPD1_TX Init */
  LL_DMA_SetPeriphRequest(DMA1, LL_DMA_CHANNEL_2, LL_DMAMUX_REQ_UCPD1_TX);

  LL_DMA_SetDataTransferDirection(DMA1, LL_DMA_CHANNEL_2, LL_DMA_DIRECTION_MEMORY_TO_PERIPH);

  LL_DMA_SetChannelPriorityLevel(DMA1, LL_DMA_CHANNEL_2, LL_DMA_PRIORITY_LOW);

  LL_DMA_SetMode(DMA1, LL_DMA_CHANNEL_2, LL_DMA_MODE_NORMAL);

  LL_DMA_SetPeriphIncMode(DMA1, LL_DMA_CHANNEL_2, LL_DMA_PERIPH_NOINCREMENT);

  LL_DMA_SetMemoryIncMode(DMA1, LL_DMA_CHANNEL_2, LL_DMA_MEMORY_INCREMENT);

  LL_DMA_SetPeriphSize(DMA1, LL_DMA_CHANNEL_2, LL_DMA_PDATAALIGN_BYTE);

  LL_DMA_SetMemorySize(DMA1, LL_DMA_CHANNEL_2, LL_DMA_MDATAALIGN_BYTE);

  /* UCPD1 interrupt Init */
  NVIC_SetPriority(UCPD1_IRQn, NVIC_EncodePriority(NVIC_GetPriorityGrouping(),5, 0));
  NVIC_EnableIRQ(UCPD1_IRQn);

}

static void MX_USART1_UART_Init(void)
{

  huart1.Instance = USART1;
  huart1.Init.BaudRate = 115200;
  huart1.Init.WordLength = UART_WORDLENGTH_8B;
  huart1.Init.StopBits = UART_STOPBITS_1;
  huart1.Init.Parity = UART_PARITY_NONE;
  huart1.Init.Mode = UART_MODE_TX_RX;
  huart1.Init.HwFlowCtl = UART_HWCONTROL_NONE;
  huart1.Init.OverSampling = UART_OVERSAMPLING_16;
  huart1.Init.OneBitSampling = UART_ONE_BIT_SAMPLE_DISABLE;
  huart1.Init.ClockPrescaler = UART_PRESCALER_DIV1;
  huart1.AdvancedInit.AdvFeatureInit = UART_ADVFEATURE_NO_INIT;
  if (HAL_UART_Init(&huart1) != HAL_OK)
  {
    Error_Handler();
  }
  if (HAL_UARTEx_SetTxFifoThreshold(&huart1, UART_TXFIFO_THRESHOLD_1_8) != HAL_OK)
  {
    Error_Handler();
  }
  if (HAL_UARTEx_SetRxFifoThreshold(&huart1, UART_RXFIFO_THRESHOLD_1_8) != HAL_OK)
  {
    Error_Handler();
  }
  if (HAL_UARTEx_DisableFifoMode(&huart1) != HAL_OK)
  {
    Error_Handler();
  }

}

static void MX_USART2_UART_Init(void)
{

  huart2.Instance = USART2;
  huart2.Init.BaudRate = 115200;
  huart2.Init.WordLength = UART_WORDLENGTH_8B;
  huart2.Init.StopBits = UART_STOPBITS_1;
  huart2.Init.Parity = UART_PARITY_NONE;
  huart2.Init.Mode = UART_MODE_TX_RX;
  huart2.Init.HwFlowCtl = UART_HWCONTROL_NONE;
  huart2.Init.OverSampling = UART_OVERSAMPLING_16;
  huart2.Init.OneBitSampling = UART_ONE_BIT_SAMPLE_DISABLE;
  huart2.Init.ClockPrescaler = UART_PRESCALER_DIV1;
  huart2.AdvancedInit.AdvFeatureInit = UART_ADVFEATURE_NO_INIT;
  if (HAL_UART_Init(&huart2) != HAL_OK)
  {
    Error_Handler();
  }
  if (HAL_UARTEx_SetTxFifoThreshold(&huart2, UART_TXFIFO_THRESHOLD_1_8) != HAL_OK)
  {
    Error_Handler();
  }
  if (HAL_UARTEx_SetRxFifoThreshold(&huart2, UART_RXFIFO_THRESHOLD_1_8) != HAL_OK)
  {
    Error_Handler();
  }
  if (HAL_UARTEx_DisableFifoMode(&huart2) != HAL_OK)
  {
    Error_Handler();
  }

}

static void MX_DMA_Init(void)
{

  /* DMA controller clock enable */
  __HAL_RCC_DMAMUX1_CLK_ENABLE();
  __HAL_RCC_DMA1_CLK_ENABLE();

  /* DMA interrupt init */
  /* DMA1_Channel1_IRQn interrupt configuration */
  NVIC_SetPriority(DMA1_Channel1_IRQn, NVIC_EncodePriority(NVIC_GetPriorityGrouping(),5, 0));
  NVIC_EnableIRQ(DMA1_Channel1_IRQn);
  /* DMA1_Channel2_IRQn interrupt configuration */
  NVIC_SetPriority(DMA1_Channel2_IRQn, NVIC_EncodePriority(NVIC_GetPriorityGrouping(),5, 0));
  NVIC_EnableIRQ(DMA1_Channel2_IRQn);
  /* DMA1_Channel3_IRQn interrupt configuration */
  HAL_NVIC_SetPriority(DMA1_Channel3_IRQn, 5, 0);
  HAL_NVIC_EnableIRQ(DMA1_Channel3_IRQn);
  /* DMA1_Channel4_IRQn interrupt configuration */
  HAL_NVIC_SetPriority(DMA1_Channel4_IRQn, 5, 0);
  HAL_NVIC_EnableIRQ(DMA1_Channel4_IRQn);
  /* DMA1_Channel5_IRQn interrupt configuration */
  HAL_NVIC_SetPriority(DMA1_Channel5_IRQn, 5, 0);
  HAL_NVIC_EnableIRQ(DMA1_Channel5_IRQn);
  /* DMA1_Channel6_IRQn interrupt configuration */
  HAL_NVIC_SetPriority(DMA1_Channel6_IRQn, 5, 0);
  HAL_NVIC_EnableIRQ(DMA1_Channel6_IRQn);
  /* DMA1_Channel7_IRQn interrupt configuration */
  HAL_NVIC_SetPriority(DMA1_Channel7_IRQn, 5, 0);
  HAL_NVIC_EnableIRQ(DMA1_Channel7_IRQn);
  /* DMA1_Channel8_IRQn interrupt configuration */
  HAL_NVIC_SetPriority(DMA1_Channel8_IRQn, 5, 0);
  HAL_NVIC_EnableIRQ(DMA1_Channel8_IRQn);

}

static void MX_GPIO_Init(void)
{
  GPIO_InitTypeDef GPIO_InitStruct = {0};

  /* GPIO Ports Clock Enable */
  __HAL_RCC_GPIOE_CLK_ENABLE();
  __HAL_RCC_GPIOB_CLK_ENABLE();
  __HAL_RCC_GPIOD_CLK_ENABLE();
  __HAL_RCC_GPIOC_CLK_ENABLE();
  __HAL_RCC_GPIOA_CLK_ENABLE();
  __HAL_RCC_GPIOF_CLK_ENABLE();
  __HAL_RCC_GPIOG_CLK_ENABLE();

  /*Configure GPIO pin Output Level */
  HAL_GPIO_WritePin(GPIOD, GPIO_PIN_1|GPIO_PIN_2|GPIO_PIN_0|GPIO_PIN_10
                          |GPIO_PIN_9|GPIO_PIN_13|GPIO_PIN_15|GPIO_PIN_8, GPIO_PIN_RESET);

  /*Configure GPIO pin Output Level */
  HAL_GPIO_WritePin(GPIOC, GPIO_PIN_15|GPIO_PIN_13, GPIO_PIN_RESET);

  /*Configure GPIO pin Output Level */
  HAL_GPIO_WritePin(GPIOE, GPIO_PIN_8|GPIO_PIN_11|GPIO_PIN_10, GPIO_PIN_RESET);

  /*Configure GPIO pins : PD1 PD2 PD0 PD10
                           PD9 PD13 PD15 PD8 */
  GPIO_InitStruct.Pin = GPIO_PIN_1|GPIO_PIN_2|GPIO_PIN_0|GPIO_PIN_10
                          |GPIO_PIN_9|GPIO_PIN_13|GPIO_PIN_15|GPIO_PIN_8;
  GPIO_InitStruct.Mode = GPIO_MODE_OUTPUT_PP;
  GPIO_InitStruct.Pull = GPIO_NOPULL;
  GPIO_InitStruct.Speed = GPIO_SPEED_FREQ_LOW;
  HAL_GPIO_Init(GPIOD, &GPIO_InitStruct);

  /*Configure GPIO pin : PB7 */
  GPIO_InitStruct.Pin = GPIO_PIN_7;
  GPIO_InitStruct.Mode = GPIO_MODE_INPUT;
  GPIO_InitStruct.Pull = GPIO_NOPULL;
  HAL_GPIO_Init(GPIOB, &GPIO_InitStruct);

  /*Configure GPIO pins : PC14 PC5 */
  GPIO_InitStruct.Pin = GPIO_PIN_14|GPIO_PIN_5;
  GPIO_InitStruct.Mode = GPIO_MODE_INPUT;
  GPIO_InitStruct.Pull = GPIO_NOPULL;
  HAL_GPIO_Init(GPIOC, &GPIO_InitStruct);

  /*Configure GPIO pins : PC15 PC13 */
  GPIO_InitStruct.Pin = GPIO_PIN_15|GPIO_PIN_13;
  GPIO_InitStruct.Mode = GPIO_MODE_OUTPUT_PP;
  GPIO_InitStruct.Pull = GPIO_NOPULL;
  GPIO_InitStruct.Speed = GPIO_SPEED_FREQ_LOW;
  HAL_GPIO_Init(GPIOC, &GPIO_InitStruct);

  /*Configure GPIO pin : PG10 */
  GPIO_InitStruct.Pin = GPIO_PIN_10;
  GPIO_InitStruct.Mode = GPIO_MODE_AF_PP;
  GPIO_InitStruct.Pull = GPIO_NOPULL;
  GPIO_InitStruct.Speed = GPIO_SPEED_FREQ_LOW;
  GPIO_InitStruct.Alternate = GPIO_AF0_MCO;
  HAL_GPIO_Init(GPIOG, &GPIO_InitStruct);

  /*Configure GPIO pins : PE8 PE11 PE10 */
  GPIO_InitStruct.Pin = GPIO_PIN_8|GPIO_PIN_11|GPIO_PIN_10;
  GPIO_InitStruct.Mode = GPIO_MODE_OUTPUT_PP;
  GPIO_InitStruct.Pull = GPIO_NOPULL;
  GPIO_InitStruct.Speed = GPIO_SPEED_FREQ_LOW;
  HAL_GPIO_Init(GPIOE, &GPIO_InitStruct);

}

void StartDefaultTask(void *argument)
{
  /* init code for USB_Device */
  MX_USB_Device_Init();
  /* USER CODE BEGIN 5 */

  controller_system_init();

  /* Infinite loop */
  for(;;)
  {
    osDelay(1);
  }
  /* USER CODE END 5 */
}

void HAL_TIM_PeriodElapsedCallback(TIM_HandleTypeDef *htim)
{
  if (htim->Instance == TIM7)
  {
    HAL_IncTick();
  }
  /* USER CODE BEGIN Callback 1 */
  if (htim->Instance == TIM7)
  {
    /* 1 kHz tick of the USB-PD PE/PRL software timers: protocol timeouts never fire otherwise.
       No RTOS calls inside; it does nothing until MX_USBPD_Init has run. */
    USBPD_DPM_TimerCounter();
  }
  /* USER CODE END Callback 1 */
}

void Error_Handler(void)
{
  __disable_irq();
  while (1)
  {
  }
}
